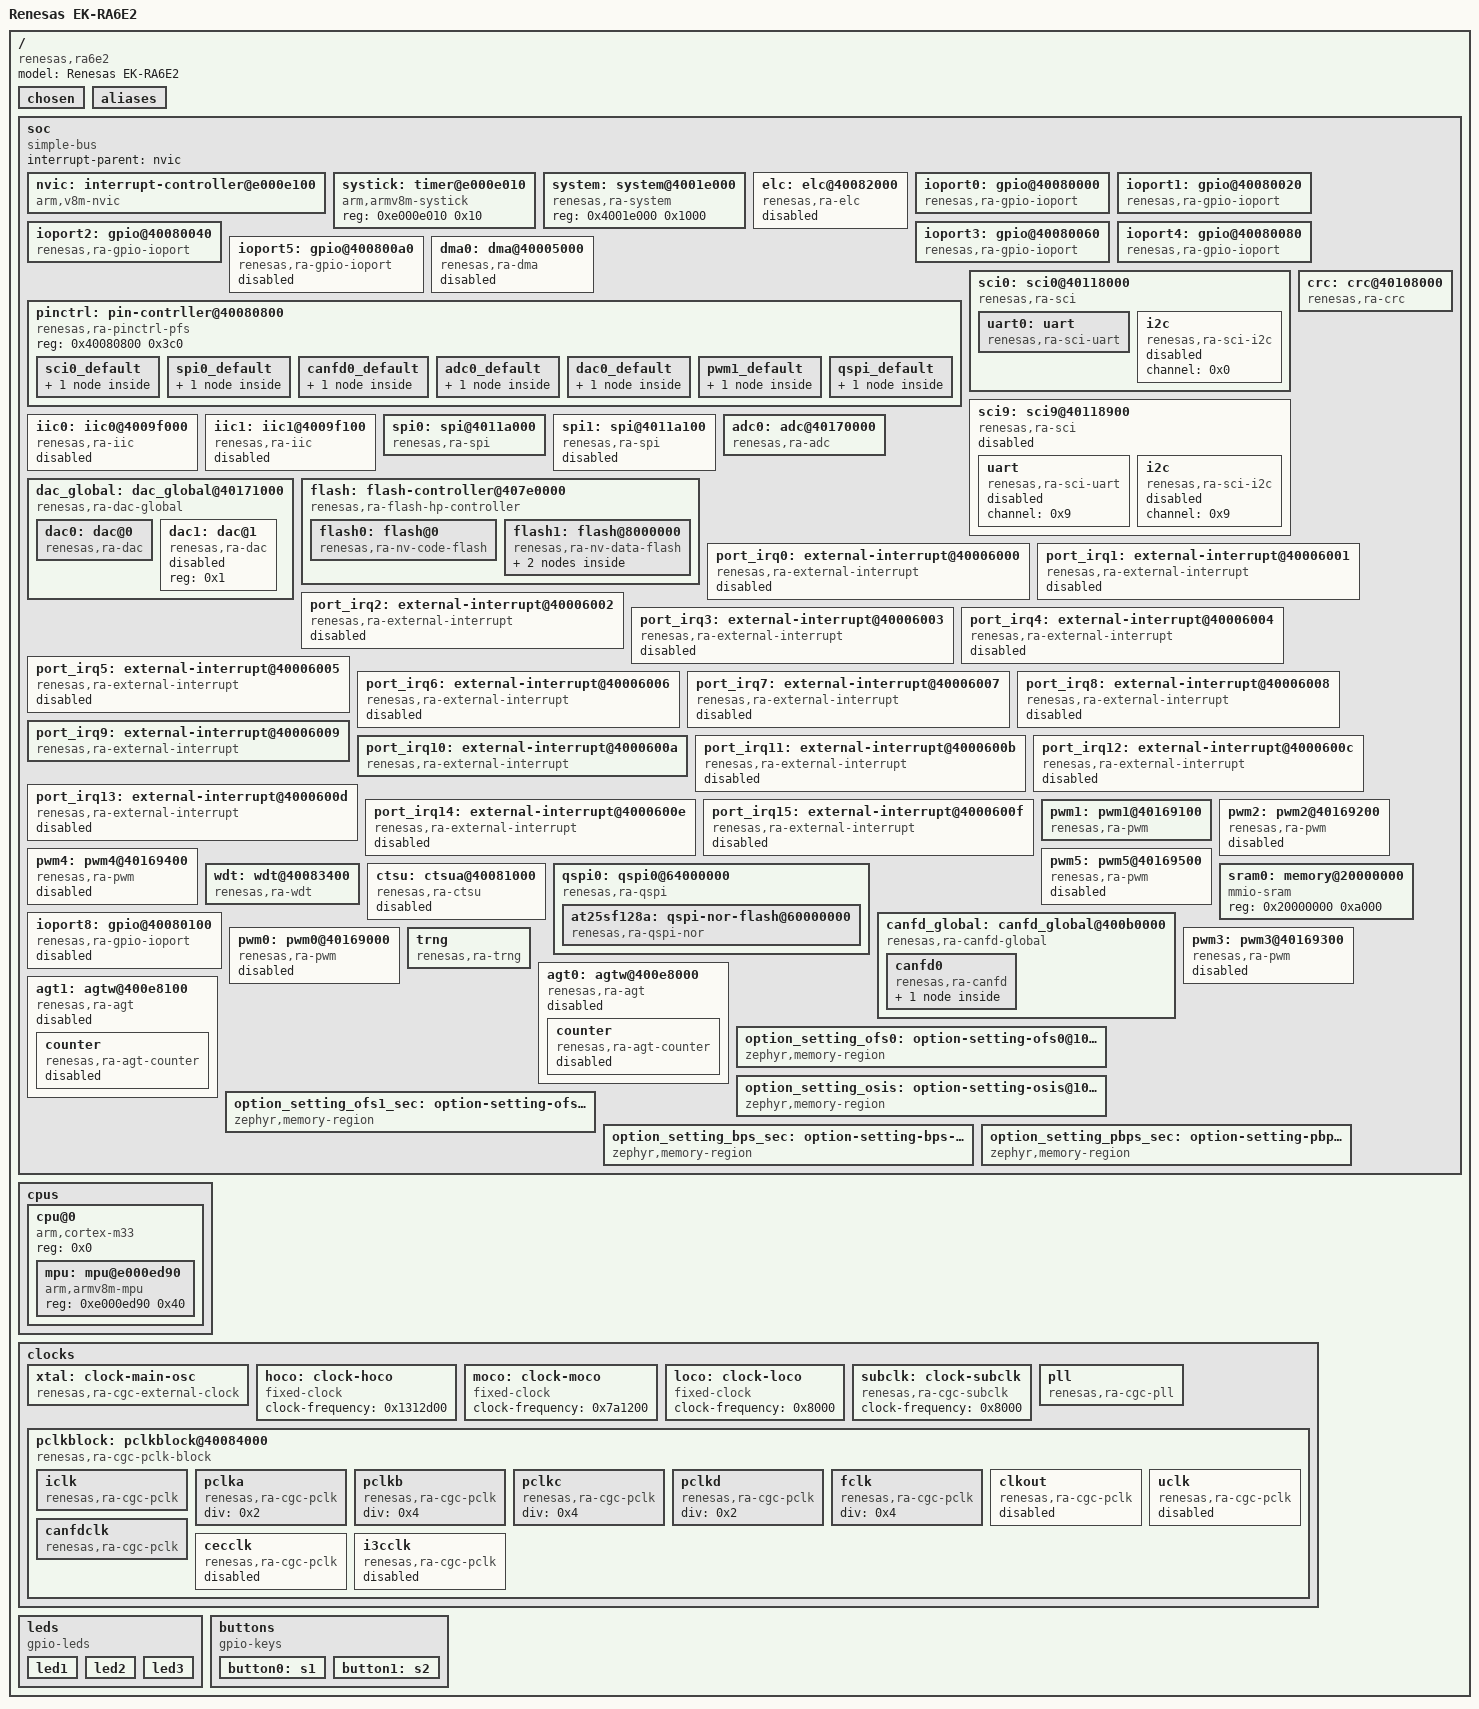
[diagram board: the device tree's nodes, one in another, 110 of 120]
/dts-v1/;

/* node '/' defined in zephyr/dts/common/skeleton.dtsi:9 */
/ {
	#address-cells = < 0x1 >;     /* in zephyr/dts/common/skeleton.dtsi:10 */
	#size-cells = < 0x1 >;        /* in zephyr/dts/common/skeleton.dtsi:11 */
	model = "Renesas EK-RA6E2";   /* in zephyr/boards/renesas/ek_ra6e2/ek_ra6e2.dts:16 */
	compatible = "renesas,ra6e2",
	             "renesas,ra";    /* in zephyr/boards/renesas/ek_ra6e2/ek_ra6e2.dts:17 */

	/* node '/chosen' defined in zephyr/dts/common/skeleton.dtsi:13 */
	chosen {
		zephyr,sram = &sram0;              /* in zephyr/boards/renesas/ek_ra6e2/ek_ra6e2.dts:20 */
		zephyr,flash-controller = &flash1; /* in zephyr/boards/renesas/ek_ra6e2/ek_ra6e2.dts:21 */
		zephyr,flash = &flash0;            /* in zephyr/boards/renesas/ek_ra6e2/ek_ra6e2.dts:22 */
		zephyr,console = &uart0;           /* in zephyr/boards/renesas/ek_ra6e2/ek_ra6e2.dts:23 */
		zephyr,shell-uart = &uart0;        /* in zephyr/boards/renesas/ek_ra6e2/ek_ra6e2.dts:24 */
		zephyr,canbus = &canfd0;           /* in zephyr/boards/renesas/ek_ra6e2/ek_ra6e2.dts:25 */
		zephyr,entropy = &trng;            /* in zephyr/boards/renesas/ek_ra6e2/ek_ra6e2.dts:26 */
		zephyr,crc = &crc;                 /* in zephyr/boards/renesas/ek_ra6e2/ek_ra6e2.dts:27 */
	};

	/* node '/aliases' defined in zephyr/dts/common/skeleton.dtsi:15 */
	aliases {
		led0 = &led1;     /* in zephyr/boards/renesas/ek_ra6e2/ek_ra6e2.dts:66 */
		sw0 = &button0;   /* in zephyr/boards/renesas/ek_ra6e2/ek_ra6e2.dts:67 */
		sw1 = &button1;   /* in zephyr/boards/renesas/ek_ra6e2/ek_ra6e2.dts:68 */
		watchdog0 = &wdt; /* in zephyr/boards/renesas/ek_ra6e2/ek_ra6e2.dts:69 */
	};

	/* node '/soc' defined in zephyr/dts/arm/armv8-m.dtsi:6 */
	soc {
		#address-cells = < 0x1 >;     /* in zephyr/dts/arm/armv8-m.dtsi:7 */
		#size-cells = < 0x1 >;        /* in zephyr/dts/arm/armv8-m.dtsi:8 */
		compatible = "simple-bus";    /* in zephyr/dts/arm/armv8-m.dtsi:9 */
		ranges;                       /* in zephyr/dts/arm/armv8-m.dtsi:11 */
		interrupt-parent = < &nvic >; /* in zephyr/dts/arm/renesas/ra/ra6/ra6-cm33-common.dtsi:34 */

		/* node '/soc/interrupt-controller@e000e100' defined in zephyr/dts/arm/armv8-m.dtsi:13 */
		nvic: interrupt-controller@e000e100 {
			#address-cells = < 0x1 >;            /* in zephyr/dts/arm/armv8-m.dtsi:14 */
			compatible = "arm,v8m-nvic";         /* in zephyr/dts/arm/armv8-m.dtsi:15 */
			reg = < 0xe000e100 0xc00 >;          /* in zephyr/dts/arm/armv8-m.dtsi:16 */
			interrupt-controller;                /* in zephyr/dts/arm/armv8-m.dtsi:17 */
			#interrupt-cells = < 0x2 >;          /* in zephyr/dts/arm/armv8-m.dtsi:18 */
			arm,num-irq-priority-bits = < 0x4 >; /* in zephyr/dts/arm/renesas/ra/ra6/ra6-cm33-common.dtsi:603 */
			phandle = < 0x1 >;                   /* in zephyr/dts/arm/renesas/ra/ra6/ra6-cm33-common.dtsi:34 */
		};

		/* node '/soc/timer@e000e010' defined in zephyr/dts/arm/armv8-m.dtsi:21 */
		systick: timer@e000e010 {
			compatible = "arm,armv8m-systick"; /* in zephyr/dts/arm/armv8-m.dtsi:22 */
			reg = < 0xe000e010 0x10 >;         /* in zephyr/dts/arm/armv8-m.dtsi:23 */
		};

		/* node '/soc/system@4001e000' defined in zephyr/dts/arm/renesas/ra/ra6/ra6-cm33-common.dtsi:36 */
		system: system@4001e000 {
			compatible = "renesas,ra-system"; /* in zephyr/dts/arm/renesas/ra/ra6/ra6-cm33-common.dtsi:37 */
			reg = < 0x4001e000 0x1000 >;      /* in zephyr/dts/arm/renesas/ra/ra6/ra6-cm33-common.dtsi:38 */
			status = "okay";                  /* in zephyr/dts/arm/renesas/ra/ra6/ra6-cm33-common.dtsi:39 */
		};

		/* node '/soc/elc@40082000' defined in zephyr/dts/arm/renesas/ra/ra6/ra6-cm33-common.dtsi:42 */
		elc: elc@40082000 {
			compatible = "renesas,ra-elc"; /* in zephyr/dts/arm/renesas/ra/ra6/ra6-cm33-common.dtsi:43 */
			reg = < 0x40082000 0x70 >;     /* in zephyr/dts/arm/renesas/ra/ra6/ra6-cm33-common.dtsi:44 */
			#renesas-elc-cells = < 0x2 >;  /* in zephyr/dts/arm/renesas/ra/ra6/ra6-cm33-common.dtsi:45 */
			clocks = < &pclkb 0x2 0xe >;   /* in zephyr/dts/arm/renesas/ra/ra6/ra6-cm33-common.dtsi:46 */
			status = "disabled";           /* in zephyr/dts/arm/renesas/ra/ra6/ra6-cm33-common.dtsi:47 */
		};

		/* node '/soc/gpio@40080000' defined in zephyr/dts/arm/renesas/ra/ra6/ra6-cm33-common.dtsi:50 */
		ioport0: gpio@40080000 {
			compatible = "renesas,ra-gpio-ioport";                                                                       /* in zephyr/dts/arm/renesas/ra/ra6/ra6-cm33-common.dtsi:51 */
			reg = < 0x40080000 0x20 >;                                                                                   /* in zephyr/dts/arm/renesas/ra/ra6/ra6-cm33-common.dtsi:52 */
			port = < 0x0 >;                                                                                              /* in zephyr/dts/arm/renesas/ra/ra6/ra6-cm33-common.dtsi:53 */
			gpio-controller;                                                                                             /* in zephyr/dts/arm/renesas/ra/ra6/ra6-cm33-common.dtsi:54 */
			#gpio-cells = < 0x2 >;                                                                                       /* in zephyr/dts/arm/renesas/ra/ra6/ra6-cm33-common.dtsi:55 */
			ngpios = < 0x10 >;                                                                                           /* in zephyr/dts/arm/renesas/ra/ra6/ra6-cm33-common.dtsi:56 */
			port-irqs = < &port_irq6 &port_irq7 &port_irq8 &port_irq9 &port_irq10 &port_irq11 &port_irq12 &port_irq13 >; /* in zephyr/dts/arm/renesas/ra/ra6/r7fa6e2bx.dtsi:291 */
			port-irq-names = "port-irq6",
			                 "port-irq7",
			                 "port-irq8",
			                 "port-irq9",
			                 "port-irq10",
			                 "port-irq11",
			                 "port-irq12",
			                 "port-irq13";                                                                               /* in zephyr/dts/arm/renesas/ra/ra6/r7fa6e2bx.dtsi:294 */
			port-irq6-pins = < 0x0 >;                                                                                    /* in zephyr/dts/arm/renesas/ra/ra6/r7fa6e2bx.dtsi:302 */
			port-irq7-pins = < 0x1 >;                                                                                    /* in zephyr/dts/arm/renesas/ra/ra6/r7fa6e2bx.dtsi:303 */
			port-irq8-pins = < 0x2 >;                                                                                    /* in zephyr/dts/arm/renesas/ra/ra6/r7fa6e2bx.dtsi:304 */
			port-irq9-pins = < 0x4 >;                                                                                    /* in zephyr/dts/arm/renesas/ra/ra6/r7fa6e2bx.dtsi:305 */
			port-irq10-pins = < 0x5 >;                                                                                   /* in zephyr/dts/arm/renesas/ra/ra6/r7fa6e2bx.dtsi:306 */
			port-irq11-pins = < 0x6 >;                                                                                   /* in zephyr/dts/arm/renesas/ra/ra6/r7fa6e2bx.dtsi:307 */
			port-irq12-pins = < 0x8 >;                                                                                   /* in zephyr/dts/arm/renesas/ra/ra6/r7fa6e2bx.dtsi:308 */
			port-irq13-pins = < 0xf >;                                                                                   /* in zephyr/dts/arm/renesas/ra/ra6/r7fa6e2bx.dtsi:309 */
			status = "okay";                                                                                             /* in zephyr/boards/renesas/ek_ra6e2/ek_ra6e2.dts:85 */
			phandle = < 0x23 >;                                                                                          /* in zephyr/boards/renesas/ek_ra6e2/ek_ra6e2.dts:53 */
		};

		/* node '/soc/gpio@40080020' defined in zephyr/dts/arm/renesas/ra/ra6/ra6-cm33-common.dtsi:60 */
		ioport1: gpio@40080020 {
			compatible = "renesas,ra-gpio-ioport";                                  /* in zephyr/dts/arm/renesas/ra/ra6/ra6-cm33-common.dtsi:61 */
			reg = < 0x40080020 0x20 >;                                              /* in zephyr/dts/arm/renesas/ra/ra6/ra6-cm33-common.dtsi:62 */
			port = < 0x1 >;                                                         /* in zephyr/dts/arm/renesas/ra/ra6/ra6-cm33-common.dtsi:63 */
			gpio-controller;                                                        /* in zephyr/dts/arm/renesas/ra/ra6/ra6-cm33-common.dtsi:64 */
			#gpio-cells = < 0x2 >;                                                  /* in zephyr/dts/arm/renesas/ra/ra6/ra6-cm33-common.dtsi:65 */
			ngpios = < 0x10 >;                                                      /* in zephyr/dts/arm/renesas/ra/ra6/ra6-cm33-common.dtsi:66 */
			port-irqs = < &port_irq0 &port_irq1 &port_irq2 &port_irq3 &port_irq4 >; /* in zephyr/dts/arm/renesas/ra/ra6/r7fa6e2bx.dtsi:313 */
			port-irq-names = "port-irq0",
			                 "port-irq1",
			                 "port-irq2",
			                 "port-irq3",
			                 "port-irq4";                                           /* in zephyr/dts/arm/renesas/ra/ra6/r7fa6e2bx.dtsi:315 */
			port-irq0-pins = < 0x5 >;                                               /* in zephyr/dts/arm/renesas/ra/ra6/r7fa6e2bx.dtsi:320 */
			port-irq1-pins = < 0x1 0x4 >;                                           /* in zephyr/dts/arm/renesas/ra/ra6/r7fa6e2bx.dtsi:321 */
			port-irq2-pins = < 0x0 >;                                               /* in zephyr/dts/arm/renesas/ra/ra6/r7fa6e2bx.dtsi:322 */
			port-irq3-pins = < 0xa >;                                               /* in zephyr/dts/arm/renesas/ra/ra6/r7fa6e2bx.dtsi:323 */
			port-irq4-pins = < 0xb >;                                               /* in zephyr/dts/arm/renesas/ra/ra6/r7fa6e2bx.dtsi:324 */
			status = "okay";                                                        /* in zephyr/boards/renesas/ek_ra6e2/ek_ra6e2.dts:89 */
			phandle = < 0x22 >;                                                     /* in zephyr/boards/renesas/ek_ra6e2/ek_ra6e2.dts:44 */
		};

		/* node '/soc/gpio@40080040' defined in zephyr/dts/arm/renesas/ra/ra6/ra6-cm33-common.dtsi:70 */
		ioport2: gpio@40080040 {
			compatible = "renesas,ra-gpio-ioport";                       /* in zephyr/dts/arm/renesas/ra/ra6/ra6-cm33-common.dtsi:71 */
			reg = < 0x40080040 0x20 >;                                   /* in zephyr/dts/arm/renesas/ra/ra6/ra6-cm33-common.dtsi:72 */
			port = < 0x2 >;                                              /* in zephyr/dts/arm/renesas/ra/ra6/ra6-cm33-common.dtsi:73 */
			gpio-controller;                                             /* in zephyr/dts/arm/renesas/ra/ra6/ra6-cm33-common.dtsi:74 */
			#gpio-cells = < 0x2 >;                                       /* in zephyr/dts/arm/renesas/ra/ra6/ra6-cm33-common.dtsi:75 */
			ngpios = < 0x10 >;                                           /* in zephyr/dts/arm/renesas/ra/ra6/ra6-cm33-common.dtsi:76 */
			port-irqs = < &port_irq0 &port_irq1 &port_irq2 &port_irq3 >; /* in zephyr/dts/arm/renesas/ra/ra6/r7fa6e2bx.dtsi:328 */
			port-irq-names = "port-irq0",
			                 "port-irq1",
			                 "port-irq2",
			                 "port-irq3";                                /* in zephyr/dts/arm/renesas/ra/ra6/r7fa6e2bx.dtsi:330 */
			port-irq0-pins = < 0x6 >;                                    /* in zephyr/dts/arm/renesas/ra/ra6/r7fa6e2bx.dtsi:334 */
			port-irq1-pins = < 0x5 >;                                    /* in zephyr/dts/arm/renesas/ra/ra6/r7fa6e2bx.dtsi:335 */
			port-irq2-pins = < 0xd >;                                    /* in zephyr/dts/arm/renesas/ra/ra6/r7fa6e2bx.dtsi:336 */
			port-irq3-pins = < 0xc >;                                    /* in zephyr/dts/arm/renesas/ra/ra6/r7fa6e2bx.dtsi:337 */
			status = "okay";                                             /* in zephyr/boards/renesas/ek_ra6e2/ek_ra6e2.dts:99 */
			phandle = < 0x20 >;                                          /* in zephyr/boards/renesas/ek_ra6e2/ek_ra6e2.dts:34 */
		};

		/* node '/soc/gpio@40080060' defined in zephyr/dts/arm/renesas/ra/ra6/ra6-cm33-common.dtsi:80 */
		ioport3: gpio@40080060 {
			compatible = "renesas,ra-gpio-ioport";            /* in zephyr/dts/arm/renesas/ra/ra6/ra6-cm33-common.dtsi:81 */
			reg = < 0x40080060 0x20 >;                        /* in zephyr/dts/arm/renesas/ra/ra6/ra6-cm33-common.dtsi:82 */
			port = < 0x3 >;                                   /* in zephyr/dts/arm/renesas/ra/ra6/ra6-cm33-common.dtsi:83 */
			gpio-controller;                                  /* in zephyr/dts/arm/renesas/ra/ra6/ra6-cm33-common.dtsi:84 */
			#gpio-cells = < 0x2 >;                            /* in zephyr/dts/arm/renesas/ra/ra6/ra6-cm33-common.dtsi:85 */
			ngpios = < 0x10 >;                                /* in zephyr/dts/arm/renesas/ra/ra6/ra6-cm33-common.dtsi:86 */
			port-irqs = < &port_irq5 &port_irq6 &port_irq9 >; /* in zephyr/dts/arm/renesas/ra/ra6/r7fa6e2bx.dtsi:341 */
			port-irq-names = "port-irq5",
			                 "port-irq6",
			                 "port-irq9";                     /* in zephyr/dts/arm/renesas/ra/ra6/r7fa6e2bx.dtsi:342 */
			port-irq5-pins = < 0x2 >;                         /* in zephyr/dts/arm/renesas/ra/ra6/r7fa6e2bx.dtsi:345 */
			port-irq6-pins = < 0x1 >;                         /* in zephyr/dts/arm/renesas/ra/ra6/r7fa6e2bx.dtsi:346 */
			port-irq9-pins = < 0x4 >;                         /* in zephyr/dts/arm/renesas/ra/ra6/r7fa6e2bx.dtsi:347 */
			status = "okay";                                  /* in zephyr/boards/renesas/ek_ra6e2/ek_ra6e2.dts:103 */
			phandle = < 0x24 >;                               /* in zephyr/boards/renesas/ek_ra6e2/ek_ra6e2.dts:59 */
		};

		/* node '/soc/gpio@40080080' defined in zephyr/dts/arm/renesas/ra/ra6/ra6-cm33-common.dtsi:90 */
		ioport4: gpio@40080080 {
			compatible = "renesas,ra-gpio-ioport";                                              /* in zephyr/dts/arm/renesas/ra/ra6/ra6-cm33-common.dtsi:91 */
			reg = < 0x40080080 0x20 >;                                                          /* in zephyr/dts/arm/renesas/ra/ra6/ra6-cm33-common.dtsi:92 */
			port = < 0x4 >;                                                                     /* in zephyr/dts/arm/renesas/ra/ra6/ra6-cm33-common.dtsi:93 */
			gpio-controller;                                                                    /* in zephyr/dts/arm/renesas/ra/ra6/ra6-cm33-common.dtsi:94 */
			#gpio-cells = < 0x2 >;                                                              /* in zephyr/dts/arm/renesas/ra/ra6/ra6-cm33-common.dtsi:95 */
			ngpios = < 0x10 >;                                                                  /* in zephyr/dts/arm/renesas/ra/ra6/ra6-cm33-common.dtsi:96 */
			port-irqs = < &port_irq0 &port_irq4 &port_irq5 &port_irq6 &port_irq7 &port_irq14 >; /* in zephyr/dts/arm/renesas/ra/ra6/r7fa6e2bx.dtsi:351 */
			port-irq-names = "port-irq0",
			                 "port-irq4",
			                 "port-irq5",
			                 "port-irq6",
			                 "port-irq7",
			                 "port-irq14";                                                      /* in zephyr/dts/arm/renesas/ra/ra6/r7fa6e2bx.dtsi:353 */
			port-irq0-pins = < 0x0 >;                                                           /* in zephyr/dts/arm/renesas/ra/ra6/r7fa6e2bx.dtsi:359 */
			port-irq4-pins = < 0x2 0xb >;                                                       /* in zephyr/dts/arm/renesas/ra/ra6/r7fa6e2bx.dtsi:360 */
			port-irq5-pins = < 0x1 0xa >;                                                       /* in zephyr/dts/arm/renesas/ra/ra6/r7fa6e2bx.dtsi:361 */
			port-irq6-pins = < 0x9 >;                                                           /* in zephyr/dts/arm/renesas/ra/ra6/r7fa6e2bx.dtsi:362 */
			port-irq7-pins = < 0x8 >;                                                           /* in zephyr/dts/arm/renesas/ra/ra6/r7fa6e2bx.dtsi:363 */
			port-irq14-pins = < 0x3 >;                                                          /* in zephyr/dts/arm/renesas/ra/ra6/r7fa6e2bx.dtsi:364 */
			status = "okay";                                                                    /* in zephyr/boards/renesas/ek_ra6e2/ek_ra6e2.dts:107 */
			phandle = < 0x21 >;                                                                 /* in zephyr/boards/renesas/ek_ra6e2/ek_ra6e2.dts:39 */
		};

		/* node '/soc/gpio@400800a0' defined in zephyr/dts/arm/renesas/ra/ra6/ra6-cm33-common.dtsi:101 */
		ioport5: gpio@400800a0 {
			compatible = "renesas,ra-gpio-ioport"; /* in zephyr/dts/arm/renesas/ra/ra6/ra6-cm33-common.dtsi:102 */
			reg = < 0x400800a0 0x20 >;             /* in zephyr/dts/arm/renesas/ra/ra6/ra6-cm33-common.dtsi:103 */
			port = < 0x5 >;                        /* in zephyr/dts/arm/renesas/ra/ra6/ra6-cm33-common.dtsi:104 */
			gpio-controller;                       /* in zephyr/dts/arm/renesas/ra/ra6/ra6-cm33-common.dtsi:105 */
			#gpio-cells = < 0x2 >;                 /* in zephyr/dts/arm/renesas/ra/ra6/ra6-cm33-common.dtsi:106 */
			ngpios = < 0x10 >;                     /* in zephyr/dts/arm/renesas/ra/ra6/ra6-cm33-common.dtsi:107 */
			status = "disabled";                   /* in zephyr/dts/arm/renesas/ra/ra6/ra6-cm33-common.dtsi:108 */
		};

		/* node '/soc/dma@40005000' defined in zephyr/dts/arm/renesas/ra/ra6/ra6-cm33-common.dtsi:111 */
		dma0: dma@40005000 {
			compatible = "renesas,ra-dma"; /* in zephyr/dts/arm/renesas/ra/ra6/ra6-cm33-common.dtsi:112 */
			reg = < 0x40005000 0x200 >,
			      < 0x40005200 0xa0 >;     /* in zephyr/dts/arm/renesas/ra/ra6/ra6-cm33-common.dtsi:113 */
			reg-names = "channel",
			            "common";          /* in zephyr/dts/arm/renesas/ra/ra6/ra6-cm33-common.dtsi:114 */
			clocks = < &iclk 0x0 0x16 >;   /* in zephyr/dts/arm/renesas/ra/ra6/ra6-cm33-common.dtsi:115 */
			dma-channels = < 0x8 >;        /* in zephyr/dts/arm/renesas/ra/ra6/ra6-cm33-common.dtsi:116 */
			#dma-cells = < 0x2 >;          /* in zephyr/dts/arm/renesas/ra/ra6/ra6-cm33-common.dtsi:117 */
			status = "disabled";           /* in zephyr/dts/arm/renesas/ra/ra6/ra6-cm33-common.dtsi:118 */
		};

		/* node '/soc/pin-contrller@40080800' defined in zephyr/dts/arm/renesas/ra/ra6/ra6-cm33-common.dtsi:121 */
		pinctrl: pin-contrller@40080800 {
			compatible = "renesas,ra-pinctrl-pfs"; /* in zephyr/dts/arm/renesas/ra/ra6/ra6-cm33-common.dtsi:122 */
			reg = < 0x40080800 0x3c0 >;            /* in zephyr/dts/arm/renesas/ra/ra6/ra6-cm33-common.dtsi:123 */
			status = "okay";                       /* in zephyr/dts/arm/renesas/ra/ra6/ra6-cm33-common.dtsi:124 */

			/* node '/soc/pin-contrller@40080800/sci0_default' defined in zephyr/boards/renesas/ek_ra6e2/ek_ra6e2-pinctrl.dtsi:7 */
			sci0_default: sci0_default {
				phandle = < 0x14 >; /* in zephyr/boards/renesas/ek_ra6e2/ek_ra6e2.dts:74 */

				/* node '/soc/pin-contrller@40080800/sci0_default/group1' defined in zephyr/boards/renesas/ek_ra6e2/ek_ra6e2-pinctrl.dtsi:8 */
				group1 {
					psels = < 0x24b4 >,
					        < 0x24a4 >; /* in zephyr/boards/renesas/ek_ra6e2/ek_ra6e2-pinctrl.dtsi:10 */
				};
			};

			/* node '/soc/pin-contrller@40080800/spi0_default' defined in zephyr/boards/renesas/ek_ra6e2/ek_ra6e2-pinctrl.dtsi:15 */
			spi0_default: spi0_default {
				phandle = < 0x15 >; /* in zephyr/boards/renesas/ek_ra6e2/ek_ra6e2.dts:93 */

				/* node '/soc/pin-contrller@40080800/spi0_default/group1' defined in zephyr/boards/renesas/ek_ra6e2/ek_ra6e2-pinctrl.dtsi:16 */
				group1 {
					psels = < 0x26a1 >,
					        < 0x2691 >,
					        < 0x26b1 >,
					        < 0x2613 >; /* in zephyr/boards/renesas/ek_ra6e2/ek_ra6e2-pinctrl.dtsi:18 */
				};
			};

			/* node '/soc/pin-contrller@40080800/canfd0_default' defined in zephyr/boards/renesas/ek_ra6e2/ek_ra6e2-pinctrl.dtsi:25 */
			canfd0_default: canfd0_default {
				phandle = < 0x1d >; /* in zephyr/boards/renesas/ek_ra6e2/ek_ra6e2.dts:138 */

				/* node '/soc/pin-contrller@40080800/canfd0_default/group1' defined in zephyr/boards/renesas/ek_ra6e2/ek_ra6e2-pinctrl.dtsi:26 */
				group1 {
					psels = < 0x3024 >,
					        < 0x3014 >;      /* in zephyr/boards/renesas/ek_ra6e2/ek_ra6e2-pinctrl.dtsi:28 */
					drive-strength = "high"; /* in zephyr/boards/renesas/ek_ra6e2/ek_ra6e2-pinctrl.dtsi:30 */
				};
			};

			/* node '/soc/pin-contrller@40080800/adc0_default' defined in zephyr/boards/renesas/ek_ra6e2/ek_ra6e2-pinctrl.dtsi:34 */
			adc0_default: adc0_default {
				phandle = < 0x16 >; /* in zephyr/boards/renesas/ek_ra6e2/ek_ra6e2.dts:151 */

				/* node '/soc/pin-contrller@40080800/adc0_default/group1' defined in zephyr/boards/renesas/ek_ra6e2/ek_ra6e2-pinctrl.dtsi:35 */
				group1 {
					psels = < 0x2000 >;    /* in zephyr/boards/renesas/ek_ra6e2/ek_ra6e2-pinctrl.dtsi:37 */
					renesas,analog-enable; /* in zephyr/boards/renesas/ek_ra6e2/ek_ra6e2-pinctrl.dtsi:38 */
				};
			};

			/* node '/soc/pin-contrller@40080800/dac0_default' defined in zephyr/boards/renesas/ek_ra6e2/ek_ra6e2-pinctrl.dtsi:42 */
			dac0_default: dac0_default {
				phandle = < 0x17 >; /* in zephyr/boards/renesas/ek_ra6e2/ek_ra6e2.dts:156 */

				/* node '/soc/pin-contrller@40080800/dac0_default/group1' defined in zephyr/boards/renesas/ek_ra6e2/ek_ra6e2-pinctrl.dtsi:43 */
				group1 {
					psels = < 0x20e0 >;    /* in zephyr/boards/renesas/ek_ra6e2/ek_ra6e2-pinctrl.dtsi:45 */
					renesas,analog-enable; /* in zephyr/boards/renesas/ek_ra6e2/ek_ra6e2-pinctrl.dtsi:46 */
				};
			};

			/* node '/soc/pin-contrller@40080800/pwm1_default' defined in zephyr/boards/renesas/ek_ra6e2/ek_ra6e2-pinctrl.dtsi:50 */
			pwm1_default: pwm1_default {
				phandle = < 0x1a >; /* in zephyr/boards/renesas/ek_ra6e2/ek_ra6e2.dts:172 */

				/* node '/soc/pin-contrller@40080800/pwm1_default/group1' defined in zephyr/boards/renesas/ek_ra6e2/ek_ra6e2-pinctrl.dtsi:51 */
				group1 {
					psels = < 0x2394 >,
					        < 0x2384 >; /* in zephyr/boards/renesas/ek_ra6e2/ek_ra6e2-pinctrl.dtsi:53 */
				};
			};

			/* node '/soc/pin-contrller@40080800/qspi_default' defined in zephyr/boards/renesas/ek_ra6e2/ek_ra6e2-pinctrl.dtsi:58 */
			qspi_default: qspi_default {
				phandle = < 0x1b >; /* in zephyr/boards/renesas/ek_ra6e2/ek_ra6e2.dts:202 */

				/* node '/soc/pin-contrller@40080800/qspi_default/group1' defined in zephyr/boards/renesas/ek_ra6e2/ek_ra6e2-pinctrl.dtsi:59 */
				group1 {
					psels = < 0x3101 >,
					        < 0x31c1 >,
					        < 0x3121 >,
					        < 0x3111 >,
					        < 0x3141 >,
					        < 0x3131 >; /* in zephyr/boards/renesas/ek_ra6e2/ek_ra6e2-pinctrl.dtsi:61 */
				};
			};
		};

		/* node '/soc/sci0@40118000' defined in zephyr/dts/arm/renesas/ra/ra6/ra6-cm33-common.dtsi:127 */
		sci0: sci0@40118000 {
			compatible = "renesas,ra-sci"; /* in zephyr/dts/arm/renesas/ra/ra6/ra6-cm33-common.dtsi:128 */
			interrupts = < 0x0 0x1 >,
			             < 0x1 0x1 >,
			             < 0x2 0x1 >,
			             < 0x3 0x1 >;      /* in zephyr/dts/arm/renesas/ra/ra6/ra6-cm33-common.dtsi:129 */
			interrupt-names = "rxi",
			                  "txi",
			                  "tei",
			                  "eri";       /* in zephyr/dts/arm/renesas/ra/ra6/ra6-cm33-common.dtsi:130 */
			reg = < 0x40118000 0x100 >;    /* in zephyr/dts/arm/renesas/ra/ra6/ra6-cm33-common.dtsi:131 */
			clocks = < &pclka 0x1 0x1f >;  /* in zephyr/dts/arm/renesas/ra/ra6/ra6-cm33-common.dtsi:132 */
			pinctrl-0 = < &sci0_default >; /* in zephyr/boards/renesas/ek_ra6e2/ek_ra6e2.dts:74 */
			pinctrl-names = "default";     /* in zephyr/boards/renesas/ek_ra6e2/ek_ra6e2.dts:75 */
			status = "okay";               /* in zephyr/boards/renesas/ek_ra6e2/ek_ra6e2.dts:76 */

			/* node '/soc/sci0@40118000/uart' defined in zephyr/dts/arm/renesas/ra/ra6/ra6-cm33-common.dtsi:135 */
			uart0: uart {
				compatible = "renesas,ra-sci-uart"; /* in zephyr/dts/arm/renesas/ra/ra6/ra6-cm33-common.dtsi:136 */
				channel = < 0x0 >;                  /* in zephyr/dts/arm/renesas/ra/ra6/ra6-cm33-common.dtsi:137 */
				current-speed = < 0x1c200 >;        /* in zephyr/boards/renesas/ek_ra6e2/ek_ra6e2.dts:79 */
				status = "okay";                    /* in zephyr/boards/renesas/ek_ra6e2/ek_ra6e2.dts:80 */
			};

			/* node '/soc/sci0@40118000/i2c' defined in zephyr/dts/arm/renesas/ra/ra6/ra6-cm33-common.dtsi:141 */
			i2c {
				compatible = "renesas,ra-sci-i2c"; /* in zephyr/dts/arm/renesas/ra/ra6/ra6-cm33-common.dtsi:142 */
				#address-cells = < 0x1 >;          /* in zephyr/dts/arm/renesas/ra/ra6/ra6-cm33-common.dtsi:143 */
				#size-cells = < 0x0 >;             /* in zephyr/dts/arm/renesas/ra/ra6/ra6-cm33-common.dtsi:144 */
				channel = < 0x0 >;                 /* in zephyr/dts/arm/renesas/ra/ra6/ra6-cm33-common.dtsi:145 */
				status = "disabled";               /* in zephyr/dts/arm/renesas/ra/ra6/ra6-cm33-common.dtsi:146 */
			};
		};

		/* node '/soc/sci9@40118900' defined in zephyr/dts/arm/renesas/ra/ra6/ra6-cm33-common.dtsi:150 */
		sci9: sci9@40118900 {
			compatible = "renesas,ra-sci"; /* in zephyr/dts/arm/renesas/ra/ra6/ra6-cm33-common.dtsi:151 */
			interrupts = < 0x4a 0x1 >,
			             < 0x4b 0x1 >,
			             < 0x4c 0x1 >,
			             < 0x4d 0x1 >;     /* in zephyr/dts/arm/renesas/ra/ra6/ra6-cm33-common.dtsi:152 */
			interrupt-names = "rxi",
			                  "txi",
			                  "tei",
			                  "eri";       /* in zephyr/dts/arm/renesas/ra/ra6/ra6-cm33-common.dtsi:153 */
			reg = < 0x40118900 0x100 >;    /* in zephyr/dts/arm/renesas/ra/ra6/ra6-cm33-common.dtsi:154 */
			clocks = < &pclka 0x1 0x16 >;  /* in zephyr/dts/arm/renesas/ra/ra6/ra6-cm33-common.dtsi:155 */
			status = "disabled";           /* in zephyr/dts/arm/renesas/ra/ra6/ra6-cm33-common.dtsi:156 */

			/* node '/soc/sci9@40118900/uart' defined in zephyr/dts/arm/renesas/ra/ra6/ra6-cm33-common.dtsi:158 */
			uart {
				compatible = "renesas,ra-sci-uart"; /* in zephyr/dts/arm/renesas/ra/ra6/ra6-cm33-common.dtsi:159 */
				channel = < 0x9 >;                  /* in zephyr/dts/arm/renesas/ra/ra6/ra6-cm33-common.dtsi:160 */
				status = "disabled";                /* in zephyr/dts/arm/renesas/ra/ra6/ra6-cm33-common.dtsi:161 */
			};

			/* node '/soc/sci9@40118900/i2c' defined in zephyr/dts/arm/renesas/ra/ra6/ra6-cm33-common.dtsi:164 */
			i2c {
				compatible = "renesas,ra-sci-i2c"; /* in zephyr/dts/arm/renesas/ra/ra6/ra6-cm33-common.dtsi:165 */
				#address-cells = < 0x1 >;          /* in zephyr/dts/arm/renesas/ra/ra6/ra6-cm33-common.dtsi:166 */
				#size-cells = < 0x0 >;             /* in zephyr/dts/arm/renesas/ra/ra6/ra6-cm33-common.dtsi:167 */
				channel = < 0x9 >;                 /* in zephyr/dts/arm/renesas/ra/ra6/ra6-cm33-common.dtsi:168 */
				status = "disabled";               /* in zephyr/dts/arm/renesas/ra/ra6/ra6-cm33-common.dtsi:169 */
			};
		};

		/* node '/soc/iic0@4009f000' defined in zephyr/dts/arm/renesas/ra/ra6/ra6-cm33-common.dtsi:173 */
		iic0: iic0@4009f000 {
			compatible = "renesas,ra-iic"; /* in zephyr/dts/arm/renesas/ra/ra6/ra6-cm33-common.dtsi:174 */
			channel = < 0x0 >;             /* in zephyr/dts/arm/renesas/ra/ra6/ra6-cm33-common.dtsi:175 */
			reg = < 0x4009f000 0x100 >;    /* in zephyr/dts/arm/renesas/ra/ra6/ra6-cm33-common.dtsi:176 */
			status = "disabled";           /* in zephyr/dts/arm/renesas/ra/ra6/ra6-cm33-common.dtsi:177 */
		};

		/* node '/soc/iic1@4009f100' defined in zephyr/dts/arm/renesas/ra/ra6/ra6-cm33-common.dtsi:180 */
		iic1: iic1@4009f100 {
			compatible = "renesas,ra-iic"; /* in zephyr/dts/arm/renesas/ra/ra6/ra6-cm33-common.dtsi:181 */
			channel = < 0x1 >;             /* in zephyr/dts/arm/renesas/ra/ra6/ra6-cm33-common.dtsi:182 */
			reg = < 0x4009f100 0x100 >;    /* in zephyr/dts/arm/renesas/ra/ra6/ra6-cm33-common.dtsi:183 */
			status = "disabled";           /* in zephyr/dts/arm/renesas/ra/ra6/ra6-cm33-common.dtsi:184 */
		};

		/* node '/soc/spi@4011a000' defined in zephyr/dts/arm/renesas/ra/ra6/ra6-cm33-common.dtsi:187 */
		spi0: spi@4011a000 {
			compatible = "renesas,ra-spi"; /* in zephyr/dts/arm/renesas/ra/ra6/ra6-cm33-common.dtsi:188 */
			#address-cells = < 0x1 >;      /* in zephyr/dts/arm/renesas/ra/ra6/ra6-cm33-common.dtsi:189 */
			#size-cells = < 0x0 >;         /* in zephyr/dts/arm/renesas/ra/ra6/ra6-cm33-common.dtsi:190 */
			channel = < 0x0 >;             /* in zephyr/dts/arm/renesas/ra/ra6/ra6-cm33-common.dtsi:191 */
			interrupts = < 0x4e 0x1 >,
			             < 0x4f 0x1 >,
			             < 0x50 0x1 >,
			             < 0x51 0x1 >;     /* in zephyr/dts/arm/renesas/ra/ra6/ra6-cm33-common.dtsi:192 */
			interrupt-names = "rxi",
			                  "txi",
			                  "tei",
			                  "eri";       /* in zephyr/dts/arm/renesas/ra/ra6/ra6-cm33-common.dtsi:193 */
			reg = < 0x4011a000 0x100 >;    /* in zephyr/dts/arm/renesas/ra/ra6/ra6-cm33-common.dtsi:194 */
			pinctrl-0 = < &spi0_default >; /* in zephyr/boards/renesas/ek_ra6e2/ek_ra6e2.dts:93 */
			pinctrl-names = "default";     /* in zephyr/boards/renesas/ek_ra6e2/ek_ra6e2.dts:94 */
			status = "okay";               /* in zephyr/boards/renesas/ek_ra6e2/ek_ra6e2.dts:95 */
		};

		/* node '/soc/spi@4011a100' defined in zephyr/dts/arm/renesas/ra/ra6/ra6-cm33-common.dtsi:198 */
		spi1: spi@4011a100 {
			compatible = "renesas,ra-spi"; /* in zephyr/dts/arm/renesas/ra/ra6/ra6-cm33-common.dtsi:199 */
			#address-cells = < 0x1 >;      /* in zephyr/dts/arm/renesas/ra/ra6/ra6-cm33-common.dtsi:200 */
			#size-cells = < 0x0 >;         /* in zephyr/dts/arm/renesas/ra/ra6/ra6-cm33-common.dtsi:201 */
			channel = < 0x1 >;             /* in zephyr/dts/arm/renesas/ra/ra6/ra6-cm33-common.dtsi:202 */
			interrupts = < 0x52 0x1 >,
			             < 0x53 0x1 >,
			             < 0x54 0x1 >,
			             < 0x55 0x1 >;     /* in zephyr/dts/arm/renesas/ra/ra6/ra6-cm33-common.dtsi:203 */
			interrupt-names = "rxi",
			                  "txi",
			                  "tei",
			                  "eri";       /* in zephyr/dts/arm/renesas/ra/ra6/ra6-cm33-common.dtsi:204 */
			reg = < 0x4011a100 0x100 >;    /* in zephyr/dts/arm/renesas/ra/ra6/ra6-cm33-common.dtsi:205 */
			status = "disabled";           /* in zephyr/dts/arm/renesas/ra/ra6/ra6-cm33-common.dtsi:206 */
		};

		/* node '/soc/adc@40170000' defined in zephyr/dts/arm/renesas/ra/ra6/ra6-cm33-common.dtsi:299 */
		adc0: adc@40170000 {
			compatible = "renesas,ra-adc";        /* in zephyr/dts/arm/renesas/ra/ra6/ra6-cm33-common.dtsi:300 */
			interrupts = < 0x26 0x1 >;            /* in zephyr/dts/arm/renesas/ra/ra6/ra6-cm33-common.dtsi:301 */
			interrupt-names = "scanend";          /* in zephyr/dts/arm/renesas/ra/ra6/ra6-cm33-common.dtsi:302 */
			reg = < 0x40170000 0x100 >;           /* in zephyr/dts/arm/renesas/ra/ra6/ra6-cm33-common.dtsi:303 */
			#io-channel-cells = < 0x1 >;          /* in zephyr/dts/arm/renesas/ra/ra6/ra6-cm33-common.dtsi:304 */
			vref-mv = < 0xce4 >;                  /* in zephyr/dts/arm/renesas/ra/ra6/ra6-cm33-common.dtsi:305 */
			channel-available-mask = < 0x139f7 >; /* in zephyr/dts/arm/renesas/ra/ra6/r7fa6e2bx.dtsi:42 */
			status = "okay";                      /* in zephyr/boards/renesas/ek_ra6e2/ek_ra6e2.dts:150 */
			pinctrl-0 = < &adc0_default >;        /* in zephyr/boards/renesas/ek_ra6e2/ek_ra6e2.dts:151 */
			pinctrl-names = "default";            /* in zephyr/boards/renesas/ek_ra6e2/ek_ra6e2.dts:152 */
		};

		/* node '/soc/crc@40108000' defined in zephyr/dts/arm/renesas/ra/ra6/ra6-cm33-common.dtsi:319 */
		crc: crc@40108000 {
			compatible = "renesas,ra-crc"; /* in zephyr/dts/arm/renesas/ra/ra6/ra6-cm33-common.dtsi:320 */
			reg = < 0x40108000 0x1000 >;   /* in zephyr/dts/arm/renesas/ra/ra6/ra6-cm33-common.dtsi:321 */
			clocks = < &pclka 0x2 0x1 >;   /* in zephyr/dts/arm/renesas/ra/ra6/ra6-cm33-common.dtsi:322 */
			status = "okay";               /* in zephyr/boards/renesas/ek_ra6e2/ek_ra6e2.dts:216 */
		};

		/* node '/soc/dac_global@40171000' defined in zephyr/dts/arm/renesas/ra/ra6/ra6-cm33-common.dtsi:326 */
		dac_global: dac_global@40171000 {
			compatible = "renesas,ra-dac-global"; /* in zephyr/dts/arm/renesas/ra/ra6/ra6-cm33-common.dtsi:327 */
			reg = < 0x40171000 0x10c4 >;          /* in zephyr/dts/arm/renesas/ra/ra6/ra6-cm33-common.dtsi:328 */
			#address-cells = < 0x1 >;             /* in zephyr/dts/arm/renesas/ra/ra6/ra6-cm33-common.dtsi:329 */
			#size-cells = < 0x0 >;                /* in zephyr/dts/arm/renesas/ra/ra6/ra6-cm33-common.dtsi:330 */
			has-output-amplifier;                 /* in zephyr/dts/arm/renesas/ra/ra6/r7fa6e2bx.dtsi:375 */

			/* node '/soc/dac_global@40171000/dac@0' defined in zephyr/dts/arm/renesas/ra/ra6/ra6-cm33-common.dtsi:332 */
			dac0: dac@0 {
				compatible = "renesas,ra-dac"; /* in zephyr/dts/arm/renesas/ra/ra6/ra6-cm33-common.dtsi:333 */
				#io-channel-cells = < 0x1 >;   /* in zephyr/dts/arm/renesas/ra/ra6/ra6-cm33-common.dtsi:334 */
				reg = < 0x0 >;                 /* in zephyr/dts/arm/renesas/ra/ra6/ra6-cm33-common.dtsi:335 */
				pinctrl-0 = < &dac0_default >; /* in zephyr/boards/renesas/ek_ra6e2/ek_ra6e2.dts:156 */
				pinctrl-names = "default";     /* in zephyr/boards/renesas/ek_ra6e2/ek_ra6e2.dts:157 */
				status = "okay";               /* in zephyr/boards/renesas/ek_ra6e2/ek_ra6e2.dts:158 */
			};

			/* node '/soc/dac_global@40171000/dac@1' defined in zephyr/dts/arm/renesas/ra/ra6/ra6-cm33-common.dtsi:339 */
			dac1: dac@1 {
				compatible = "renesas,ra-dac"; /* in zephyr/dts/arm/renesas/ra/ra6/ra6-cm33-common.dtsi:340 */
				#io-channel-cells = < 0x1 >;   /* in zephyr/dts/arm/renesas/ra/ra6/ra6-cm33-common.dtsi:341 */
				reg = < 0x1 >;                 /* in zephyr/dts/arm/renesas/ra/ra6/ra6-cm33-common.dtsi:342 */
				status = "disabled";           /* in zephyr/dts/arm/renesas/ra/ra6/ra6-cm33-common.dtsi:343 */
			};
		};

		/* node '/soc/flash-controller@407e0000' defined in zephyr/dts/arm/renesas/ra/ra6/ra6-cm33-common.dtsi:363 */
		flash: flash-controller@407e0000 {
			compatible = "renesas,ra-flash-hp-controller"; /* in zephyr/dts/arm/renesas/ra/ra6/ra6-cm33-common.dtsi:364 */
			reg = < 0x407e0000 0x10000 >;                  /* in zephyr/dts/arm/renesas/ra/ra6/ra6-cm33-common.dtsi:365 */
			#address-cells = < 0x1 >;                      /* in zephyr/dts/arm/renesas/ra/ra6/ra6-cm33-common.dtsi:366 */
			#size-cells = < 0x1 >;                         /* in zephyr/dts/arm/renesas/ra/ra6/ra6-cm33-common.dtsi:367 */
			interrupts = < 0x31 0x1 >,
			             < 0x32 0x1 >;                     /* in zephyr/dts/arm/renesas/ra/ra6/ra6-cm33-common.dtsi:368 */
			interrupt-names = "frdyi",
			                  "fiferr";                    /* in zephyr/dts/arm/renesas/ra/ra6/ra6-cm33-common.dtsi:369 */
			flash-hardware-version = < 0x28 >;             /* in zephyr/dts/arm/renesas/ra/ra6/r7fa6e2bb3cfm.dtsi:12 */
			#erase-block-cells = < 0x2 >;                  /* in zephyr/dts/arm/renesas/ra/ra6/r7fa6e2bb3cfm.dtsi:13 */
			phandle = < 0x18 >;                            /* in zephyr/dts/arm/renesas/ra/ra6/r7fa6e2bb3cfm.dtsi:20 */

			/* node '/soc/flash-controller@407e0000/flash@0' defined in zephyr/dts/arm/renesas/ra/ra6/r7fa6e2bb3cfm.dtsi:15 */
			flash0: flash@0 {
				compatible = "renesas,ra-nv-code-flash"; /* in zephyr/dts/arm/renesas/ra/ra6/r7fa6e2bb3cfm.dtsi:16 */
				reg = < 0x0 0x40000 >;                   /* in zephyr/dts/arm/renesas/ra/ra6/r7fa6e2bb3cfm.dtsi:17 */
				write-block-size = < 0x80 >;             /* in zephyr/dts/arm/renesas/ra/ra6/r7fa6e2bb3cfm.dtsi:18 */
				erase-block-size = < 0x8000 >;           /* in zephyr/dts/arm/renesas/ra/ra6/r7fa6e2bb3cfm.dtsi:19 */
				erase-blocks = < &flash 0x8 0x2000 >,
				               < &flash 0x6 0x8000 >;    /* in zephyr/dts/arm/renesas/ra/ra6/r7fa6e2bb3cfm.dtsi:20 */
				programming-enable;                      /* in zephyr/dts/arm/renesas/ra/ra6/r7fa6e2bb3cfm.dtsi:21 */
			};

			/* node '/soc/flash-controller@407e0000/flash@8000000' defined in zephyr/dts/arm/renesas/ra/ra6/r7fa6e2bb3cfm.dtsi:24 */
			flash1: flash@8000000 {
				compatible = "renesas,ra-nv-data-flash"; /* in zephyr/dts/arm/renesas/ra/ra6/r7fa6e2bb3cfm.dtsi:25 */
				reg = < 0x8000000 0x1000 >;              /* in zephyr/dts/arm/renesas/ra/ra6/r7fa6e2bb3cfm.dtsi:26 */
				write-block-size = < 0x4 >;              /* in zephyr/dts/arm/renesas/ra/ra6/r7fa6e2bb3cfm.dtsi:27 */
				erase-block-size = < 0x40 >;             /* in zephyr/dts/arm/renesas/ra/ra6/r7fa6e2bb3cfm.dtsi:28 */
				programming-enable;                      /* in zephyr/dts/arm/renesas/ra/ra6/r7fa6e2bb3cfm.dtsi:29 */
				erase-value-undefined;                   /* in zephyr/dts/arm/renesas/ra/ra6/r7fa6e2bb3cfm.dtsi:30 */

				/* node '/soc/flash-controller@407e0000/flash@8000000/partitions' defined in zephyr/boards/renesas/ek_ra6e2/ek_ra6e2.dts:185 */
				partitions {
					compatible = "fixed-partitions"; /* in zephyr/boards/renesas/ek_ra6e2/ek_ra6e2.dts:186 */
					#address-cells = < 0x1 >;        /* in zephyr/boards/renesas/ek_ra6e2/ek_ra6e2.dts:187 */
					#size-cells = < 0x1 >;           /* in zephyr/boards/renesas/ek_ra6e2/ek_ra6e2.dts:188 */

					/* node '/soc/flash-controller@407e0000/flash@8000000/partitions/partition@0' defined in zephyr/boards/renesas/ek_ra6e2/ek_ra6e2.dts:190 */
					storage_partition: partition@0 {
						label = "storage";    /* in zephyr/boards/renesas/ek_ra6e2/ek_ra6e2.dts:191 */
						reg = < 0x0 0x1000 >; /* in zephyr/boards/renesas/ek_ra6e2/ek_ra6e2.dts:192 */
					};
				};
			};
		};

		/* node '/soc/external-interrupt@40006000' defined in zephyr/dts/arm/renesas/ra/ra6/ra6-cm33-common.dtsi:372 */
		port_irq0: external-interrupt@40006000 {
			compatible = "renesas,ra-external-interrupt"; /* in zephyr/dts/arm/renesas/ra/ra6/ra6-cm33-common.dtsi:373 */
			reg = < 0x40006000 0x1 >;                     /* in zephyr/dts/arm/renesas/ra/ra6/ra6-cm33-common.dtsi:374 */
			channel = < 0x0 >;                            /* in zephyr/dts/arm/renesas/ra/ra6/ra6-cm33-common.dtsi:375 */
			renesas,sample-clock-div = < 0x40 >;          /* in zephyr/dts/arm/renesas/ra/ra6/ra6-cm33-common.dtsi:376 */
			#port-irq-cells = < 0x0 >;                    /* in zephyr/dts/arm/renesas/ra/ra6/ra6-cm33-common.dtsi:377 */
			status = "disabled";                          /* in zephyr/dts/arm/renesas/ra/ra6/ra6-cm33-common.dtsi:378 */
			phandle = < 0xb >;                            /* in zephyr/dts/arm/renesas/ra/ra6/r7fa6e2bx.dtsi:313 */
		};

		/* node '/soc/external-interrupt@40006001' defined in zephyr/dts/arm/renesas/ra/ra6/ra6-cm33-common.dtsi:381 */
		port_irq1: external-interrupt@40006001 {
			compatible = "renesas,ra-external-interrupt"; /* in zephyr/dts/arm/renesas/ra/ra6/ra6-cm33-common.dtsi:382 */
			reg = < 0x40006001 0x1 >;                     /* in zephyr/dts/arm/renesas/ra/ra6/ra6-cm33-common.dtsi:383 */
			channel = < 0x1 >;                            /* in zephyr/dts/arm/renesas/ra/ra6/ra6-cm33-common.dtsi:384 */
			renesas,sample-clock-div = < 0x40 >;          /* in zephyr/dts/arm/renesas/ra/ra6/ra6-cm33-common.dtsi:385 */
			#port-irq-cells = < 0x0 >;                    /* in zephyr/dts/arm/renesas/ra/ra6/ra6-cm33-common.dtsi:386 */
			status = "disabled";                          /* in zephyr/dts/arm/renesas/ra/ra6/ra6-cm33-common.dtsi:387 */
			phandle = < 0xc >;                            /* in zephyr/dts/arm/renesas/ra/ra6/r7fa6e2bx.dtsi:313 */
		};

		/* node '/soc/external-interrupt@40006002' defined in zephyr/dts/arm/renesas/ra/ra6/ra6-cm33-common.dtsi:390 */
		port_irq2: external-interrupt@40006002 {
			compatible = "renesas,ra-external-interrupt"; /* in zephyr/dts/arm/renesas/ra/ra6/ra6-cm33-common.dtsi:391 */
			reg = < 0x40006002 0x1 >;                     /* in zephyr/dts/arm/renesas/ra/ra6/ra6-cm33-common.dtsi:392 */
			channel = < 0x2 >;                            /* in zephyr/dts/arm/renesas/ra/ra6/ra6-cm33-common.dtsi:393 */
			renesas,sample-clock-div = < 0x40 >;          /* in zephyr/dts/arm/renesas/ra/ra6/ra6-cm33-common.dtsi:394 */
			#port-irq-cells = < 0x0 >;                    /* in zephyr/dts/arm/renesas/ra/ra6/ra6-cm33-common.dtsi:395 */
			status = "disabled";                          /* in zephyr/dts/arm/renesas/ra/ra6/ra6-cm33-common.dtsi:396 */
			phandle = < 0xd >;                            /* in zephyr/dts/arm/renesas/ra/ra6/r7fa6e2bx.dtsi:313 */
		};

		/* node '/soc/external-interrupt@40006003' defined in zephyr/dts/arm/renesas/ra/ra6/ra6-cm33-common.dtsi:399 */
		port_irq3: external-interrupt@40006003 {
			compatible = "renesas,ra-external-interrupt"; /* in zephyr/dts/arm/renesas/ra/ra6/ra6-cm33-common.dtsi:400 */
			reg = < 0x40006003 0x1 >;                     /* in zephyr/dts/arm/renesas/ra/ra6/ra6-cm33-common.dtsi:401 */
			channel = < 0x3 >;                            /* in zephyr/dts/arm/renesas/ra/ra6/ra6-cm33-common.dtsi:402 */
			renesas,sample-clock-div = < 0x40 >;          /* in zephyr/dts/arm/renesas/ra/ra6/ra6-cm33-common.dtsi:403 */
			#port-irq-cells = < 0x0 >;                    /* in zephyr/dts/arm/renesas/ra/ra6/ra6-cm33-common.dtsi:404 */
			status = "disabled";                          /* in zephyr/dts/arm/renesas/ra/ra6/ra6-cm33-common.dtsi:405 */
			phandle = < 0xe >;                            /* in zephyr/dts/arm/renesas/ra/ra6/r7fa6e2bx.dtsi:313 */
		};

		/* node '/soc/external-interrupt@40006004' defined in zephyr/dts/arm/renesas/ra/ra6/ra6-cm33-common.dtsi:408 */
		port_irq4: external-interrupt@40006004 {
			compatible = "renesas,ra-external-interrupt"; /* in zephyr/dts/arm/renesas/ra/ra6/ra6-cm33-common.dtsi:409 */
			reg = < 0x40006004 0x1 >;                     /* in zephyr/dts/arm/renesas/ra/ra6/ra6-cm33-common.dtsi:410 */
			channel = < 0x4 >;                            /* in zephyr/dts/arm/renesas/ra/ra6/ra6-cm33-common.dtsi:411 */
			renesas,sample-clock-div = < 0x40 >;          /* in zephyr/dts/arm/renesas/ra/ra6/ra6-cm33-common.dtsi:412 */
			#port-irq-cells = < 0x0 >;                    /* in zephyr/dts/arm/renesas/ra/ra6/ra6-cm33-common.dtsi:413 */
			status = "disabled";                          /* in zephyr/dts/arm/renesas/ra/ra6/ra6-cm33-common.dtsi:414 */
			phandle = < 0xf >;                            /* in zephyr/dts/arm/renesas/ra/ra6/r7fa6e2bx.dtsi:313 */
		};

		/* node '/soc/external-interrupt@40006005' defined in zephyr/dts/arm/renesas/ra/ra6/ra6-cm33-common.dtsi:417 */
		port_irq5: external-interrupt@40006005 {
			compatible = "renesas,ra-external-interrupt"; /* in zephyr/dts/arm/renesas/ra/ra6/ra6-cm33-common.dtsi:418 */
			reg = < 0x40006005 0x1 >;                     /* in zephyr/dts/arm/renesas/ra/ra6/ra6-cm33-common.dtsi:419 */
			channel = < 0x5 >;                            /* in zephyr/dts/arm/renesas/ra/ra6/ra6-cm33-common.dtsi:420 */
			renesas,sample-clock-div = < 0x40 >;          /* in zephyr/dts/arm/renesas/ra/ra6/ra6-cm33-common.dtsi:421 */
			#port-irq-cells = < 0x0 >;                    /* in zephyr/dts/arm/renesas/ra/ra6/ra6-cm33-common.dtsi:422 */
			status = "disabled";                          /* in zephyr/dts/arm/renesas/ra/ra6/ra6-cm33-common.dtsi:423 */
			phandle = < 0x10 >;                           /* in zephyr/dts/arm/renesas/ra/ra6/r7fa6e2bx.dtsi:341 */
		};

		/* node '/soc/external-interrupt@40006006' defined in zephyr/dts/arm/renesas/ra/ra6/ra6-cm33-common.dtsi:426 */
		port_irq6: external-interrupt@40006006 {
			compatible = "renesas,ra-external-interrupt"; /* in zephyr/dts/arm/renesas/ra/ra6/ra6-cm33-common.dtsi:427 */
			reg = < 0x40006006 0x1 >;                     /* in zephyr/dts/arm/renesas/ra/ra6/ra6-cm33-common.dtsi:428 */
			channel = < 0x6 >;                            /* in zephyr/dts/arm/renesas/ra/ra6/ra6-cm33-common.dtsi:429 */
			renesas,sample-clock-div = < 0x40 >;          /* in zephyr/dts/arm/renesas/ra/ra6/ra6-cm33-common.dtsi:430 */
			#port-irq-cells = < 0x0 >;                    /* in zephyr/dts/arm/renesas/ra/ra6/ra6-cm33-common.dtsi:431 */
			status = "disabled";                          /* in zephyr/dts/arm/renesas/ra/ra6/ra6-cm33-common.dtsi:432 */
			phandle = < 0x3 >;                            /* in zephyr/dts/arm/renesas/ra/ra6/r7fa6e2bx.dtsi:291 */
		};

		/* node '/soc/external-interrupt@40006007' defined in zephyr/dts/arm/renesas/ra/ra6/ra6-cm33-common.dtsi:435 */
		port_irq7: external-interrupt@40006007 {
			compatible = "renesas,ra-external-interrupt"; /* in zephyr/dts/arm/renesas/ra/ra6/ra6-cm33-common.dtsi:436 */
			reg = < 0x40006007 0x1 >;                     /* in zephyr/dts/arm/renesas/ra/ra6/ra6-cm33-common.dtsi:437 */
			channel = < 0x7 >;                            /* in zephyr/dts/arm/renesas/ra/ra6/ra6-cm33-common.dtsi:438 */
			renesas,sample-clock-div = < 0x40 >;          /* in zephyr/dts/arm/renesas/ra/ra6/ra6-cm33-common.dtsi:439 */
			#port-irq-cells = < 0x0 >;                    /* in zephyr/dts/arm/renesas/ra/ra6/ra6-cm33-common.dtsi:440 */
			status = "disabled";                          /* in zephyr/dts/arm/renesas/ra/ra6/ra6-cm33-common.dtsi:441 */
			phandle = < 0x4 >;                            /* in zephyr/dts/arm/renesas/ra/ra6/r7fa6e2bx.dtsi:291 */
		};

		/* node '/soc/external-interrupt@40006008' defined in zephyr/dts/arm/renesas/ra/ra6/ra6-cm33-common.dtsi:444 */
		port_irq8: external-interrupt@40006008 {
			compatible = "renesas,ra-external-interrupt"; /* in zephyr/dts/arm/renesas/ra/ra6/ra6-cm33-common.dtsi:445 */
			reg = < 0x40006008 0x1 >;                     /* in zephyr/dts/arm/renesas/ra/ra6/ra6-cm33-common.dtsi:446 */
			channel = < 0x8 >;                            /* in zephyr/dts/arm/renesas/ra/ra6/ra6-cm33-common.dtsi:447 */
			renesas,sample-clock-div = < 0x40 >;          /* in zephyr/dts/arm/renesas/ra/ra6/ra6-cm33-common.dtsi:448 */
			#port-irq-cells = < 0x0 >;                    /* in zephyr/dts/arm/renesas/ra/ra6/ra6-cm33-common.dtsi:449 */
			status = "disabled";                          /* in zephyr/dts/arm/renesas/ra/ra6/ra6-cm33-common.dtsi:450 */
			phandle = < 0x5 >;                            /* in zephyr/dts/arm/renesas/ra/ra6/r7fa6e2bx.dtsi:291 */
		};

		/* node '/soc/external-interrupt@40006009' defined in zephyr/dts/arm/renesas/ra/ra6/ra6-cm33-common.dtsi:453 */
		port_irq9: external-interrupt@40006009 {
			compatible = "renesas,ra-external-interrupt"; /* in zephyr/dts/arm/renesas/ra/ra6/ra6-cm33-common.dtsi:454 */
			reg = < 0x40006009 0x1 >;                     /* in zephyr/dts/arm/renesas/ra/ra6/ra6-cm33-common.dtsi:455 */
			channel = < 0x9 >;                            /* in zephyr/dts/arm/renesas/ra/ra6/ra6-cm33-common.dtsi:456 */
			renesas,sample-clock-div = < 0x40 >;          /* in zephyr/dts/arm/renesas/ra/ra6/ra6-cm33-common.dtsi:457 */
			#port-irq-cells = < 0x0 >;                    /* in zephyr/dts/arm/renesas/ra/ra6/ra6-cm33-common.dtsi:458 */
			interrupts = < 0x4 0xc >;                     /* in zephyr/boards/renesas/ek_ra6e2/ek_ra6e2.dts:162 */
			status = "okay";                              /* in zephyr/boards/renesas/ek_ra6e2/ek_ra6e2.dts:163 */
			phandle = < 0x6 >;                            /* in zephyr/dts/arm/renesas/ra/ra6/r7fa6e2bx.dtsi:291 */
		};

		/* node '/soc/external-interrupt@4000600a' defined in zephyr/dts/arm/renesas/ra/ra6/ra6-cm33-common.dtsi:462 */
		port_irq10: external-interrupt@4000600a {
			compatible = "renesas,ra-external-interrupt"; /* in zephyr/dts/arm/renesas/ra/ra6/ra6-cm33-common.dtsi:463 */
			reg = < 0x4000600a 0x1 >;                     /* in zephyr/dts/arm/renesas/ra/ra6/ra6-cm33-common.dtsi:464 */
			channel = < 0xa >;                            /* in zephyr/dts/arm/renesas/ra/ra6/ra6-cm33-common.dtsi:465 */
			renesas,sample-clock-div = < 0x40 >;          /* in zephyr/dts/arm/renesas/ra/ra6/ra6-cm33-common.dtsi:466 */
			#port-irq-cells = < 0x0 >;                    /* in zephyr/dts/arm/renesas/ra/ra6/ra6-cm33-common.dtsi:467 */
			interrupts = < 0x5 0xc >;                     /* in zephyr/boards/renesas/ek_ra6e2/ek_ra6e2.dts:167 */
			status = "okay";                              /* in zephyr/boards/renesas/ek_ra6e2/ek_ra6e2.dts:168 */
			phandle = < 0x7 >;                            /* in zephyr/dts/arm/renesas/ra/ra6/r7fa6e2bx.dtsi:291 */
		};

		/* node '/soc/external-interrupt@4000600b' defined in zephyr/dts/arm/renesas/ra/ra6/ra6-cm33-common.dtsi:471 */
		port_irq11: external-interrupt@4000600b {
			compatible = "renesas,ra-external-interrupt"; /* in zephyr/dts/arm/renesas/ra/ra6/ra6-cm33-common.dtsi:472 */
			reg = < 0x4000600b 0x1 >;                     /* in zephyr/dts/arm/renesas/ra/ra6/ra6-cm33-common.dtsi:473 */
			channel = < 0xb >;                            /* in zephyr/dts/arm/renesas/ra/ra6/ra6-cm33-common.dtsi:474 */
			renesas,sample-clock-div = < 0x40 >;          /* in zephyr/dts/arm/renesas/ra/ra6/ra6-cm33-common.dtsi:475 */
			#port-irq-cells = < 0x0 >;                    /* in zephyr/dts/arm/renesas/ra/ra6/ra6-cm33-common.dtsi:476 */
			status = "disabled";                          /* in zephyr/dts/arm/renesas/ra/ra6/ra6-cm33-common.dtsi:477 */
			phandle = < 0x8 >;                            /* in zephyr/dts/arm/renesas/ra/ra6/r7fa6e2bx.dtsi:291 */
		};

		/* node '/soc/external-interrupt@4000600c' defined in zephyr/dts/arm/renesas/ra/ra6/ra6-cm33-common.dtsi:480 */
		port_irq12: external-interrupt@4000600c {
			compatible = "renesas,ra-external-interrupt"; /* in zephyr/dts/arm/renesas/ra/ra6/ra6-cm33-common.dtsi:481 */
			reg = < 0x4000600c 0x1 >;                     /* in zephyr/dts/arm/renesas/ra/ra6/ra6-cm33-common.dtsi:482 */
			channel = < 0xc >;                            /* in zephyr/dts/arm/renesas/ra/ra6/ra6-cm33-common.dtsi:483 */
			renesas,sample-clock-div = < 0x40 >;          /* in zephyr/dts/arm/renesas/ra/ra6/ra6-cm33-common.dtsi:484 */
			#port-irq-cells = < 0x0 >;                    /* in zephyr/dts/arm/renesas/ra/ra6/ra6-cm33-common.dtsi:485 */
			status = "disabled";                          /* in zephyr/dts/arm/renesas/ra/ra6/ra6-cm33-common.dtsi:486 */
			phandle = < 0x9 >;                            /* in zephyr/dts/arm/renesas/ra/ra6/r7fa6e2bx.dtsi:291 */
		};

		/* node '/soc/external-interrupt@4000600d' defined in zephyr/dts/arm/renesas/ra/ra6/ra6-cm33-common.dtsi:489 */
		port_irq13: external-interrupt@4000600d {
			compatible = "renesas,ra-external-interrupt"; /* in zephyr/dts/arm/renesas/ra/ra6/ra6-cm33-common.dtsi:490 */
			reg = < 0x4000600d 0x1 >;                     /* in zephyr/dts/arm/renesas/ra/ra6/ra6-cm33-common.dtsi:491 */
			channel = < 0xd >;                            /* in zephyr/dts/arm/renesas/ra/ra6/ra6-cm33-common.dtsi:492 */
			renesas,sample-clock-div = < 0x40 >;          /* in zephyr/dts/arm/renesas/ra/ra6/ra6-cm33-common.dtsi:493 */
			#port-irq-cells = < 0x0 >;                    /* in zephyr/dts/arm/renesas/ra/ra6/ra6-cm33-common.dtsi:494 */
			status = "disabled";                          /* in zephyr/dts/arm/renesas/ra/ra6/ra6-cm33-common.dtsi:495 */
			phandle = < 0xa >;                            /* in zephyr/dts/arm/renesas/ra/ra6/r7fa6e2bx.dtsi:291 */
		};

		/* node '/soc/external-interrupt@4000600e' defined in zephyr/dts/arm/renesas/ra/ra6/ra6-cm33-common.dtsi:498 */
		port_irq14: external-interrupt@4000600e {
			compatible = "renesas,ra-external-interrupt"; /* in zephyr/dts/arm/renesas/ra/ra6/ra6-cm33-common.dtsi:499 */
			reg = < 0x4000600e 0x1 >;                     /* in zephyr/dts/arm/renesas/ra/ra6/ra6-cm33-common.dtsi:500 */
			channel = < 0xe >;                            /* in zephyr/dts/arm/renesas/ra/ra6/ra6-cm33-common.dtsi:501 */
			renesas,sample-clock-div = < 0x40 >;          /* in zephyr/dts/arm/renesas/ra/ra6/ra6-cm33-common.dtsi:502 */
			#port-irq-cells = < 0x0 >;                    /* in zephyr/dts/arm/renesas/ra/ra6/ra6-cm33-common.dtsi:503 */
			status = "disabled";                          /* in zephyr/dts/arm/renesas/ra/ra6/ra6-cm33-common.dtsi:504 */
			phandle = < 0x11 >;                           /* in zephyr/dts/arm/renesas/ra/ra6/r7fa6e2bx.dtsi:351 */
		};

		/* node '/soc/external-interrupt@4000600f' defined in zephyr/dts/arm/renesas/ra/ra6/ra6-cm33-common.dtsi:507 */
		port_irq15: external-interrupt@4000600f {
			compatible = "renesas,ra-external-interrupt"; /* in zephyr/dts/arm/renesas/ra/ra6/ra6-cm33-common.dtsi:508 */
			reg = < 0x4000600f 0x1 >;                     /* in zephyr/dts/arm/renesas/ra/ra6/ra6-cm33-common.dtsi:509 */
			channel = < 0xf >;                            /* in zephyr/dts/arm/renesas/ra/ra6/ra6-cm33-common.dtsi:510 */
			renesas,sample-clock-div = < 0x40 >;          /* in zephyr/dts/arm/renesas/ra/ra6/ra6-cm33-common.dtsi:511 */
			#port-irq-cells = < 0x0 >;                    /* in zephyr/dts/arm/renesas/ra/ra6/ra6-cm33-common.dtsi:512 */
			status = "disabled";                          /* in zephyr/dts/arm/renesas/ra/ra6/ra6-cm33-common.dtsi:513 */
		};

		/* node '/soc/pwm1@40169100' defined in zephyr/dts/arm/renesas/ra/ra6/ra6-cm33-common.dtsi:516 */
		pwm1: pwm1@40169100 {
			compatible = "renesas,ra-pwm"; /* in zephyr/dts/arm/renesas/ra/ra6/ra6-cm33-common.dtsi:517 */
			channel = < 0x1 >;             /* in zephyr/dts/arm/renesas/ra/ra6/ra6-cm33-common.dtsi:519 */
			clocks = < &pclkd 0x4 0x1e >;  /* in zephyr/dts/arm/renesas/ra/ra6/ra6-cm33-common.dtsi:520 */
			reg = < 0x40169100 0x100 >;    /* in zephyr/dts/arm/renesas/ra/ra6/ra6-cm33-common.dtsi:521 */
			#pwm-cells = < 0x3 >;          /* in zephyr/dts/arm/renesas/ra/ra6/ra6-cm33-common.dtsi:522 */
			pinctrl-0 = < &pwm1_default >; /* in zephyr/boards/renesas/ek_ra6e2/ek_ra6e2.dts:172 */
			pinctrl-names = "default";     /* in zephyr/boards/renesas/ek_ra6e2/ek_ra6e2.dts:173 */
			interrupts = < 0x3f 0x1 >,
			             < 0x40 0x1 >;     /* in zephyr/boards/renesas/ek_ra6e2/ek_ra6e2.dts:174 */
			interrupt-names = "gtioca",
			                  "overflow";  /* in zephyr/boards/renesas/ek_ra6e2/ek_ra6e2.dts:175 */
			divider = < 0x8 >;             /* in zephyr/boards/renesas/ek_ra6e2/ek_ra6e2.dts:176 */
			status = "okay";               /* in zephyr/boards/renesas/ek_ra6e2/ek_ra6e2.dts:177 */
		};

		/* node '/soc/pwm2@40169200' defined in zephyr/dts/arm/renesas/ra/ra6/ra6-cm33-common.dtsi:526 */
		pwm2: pwm2@40169200 {
			compatible = "renesas,ra-pwm"; /* in zephyr/dts/arm/renesas/ra/ra6/ra6-cm33-common.dtsi:527 */
			divider = < 0x0 >;             /* in zephyr/dts/arm/renesas/ra/ra6/ra6-cm33-common.dtsi:528 */
			channel = < 0x2 >;             /* in zephyr/dts/arm/renesas/ra/ra6/ra6-cm33-common.dtsi:529 */
			clocks = < &pclkd 0x4 0x1d >;  /* in zephyr/dts/arm/renesas/ra/ra6/ra6-cm33-common.dtsi:530 */
			reg = < 0x40169200 0x100 >;    /* in zephyr/dts/arm/renesas/ra/ra6/ra6-cm33-common.dtsi:531 */
			#pwm-cells = < 0x3 >;          /* in zephyr/dts/arm/renesas/ra/ra6/ra6-cm33-common.dtsi:532 */
			status = "disabled";           /* in zephyr/dts/arm/renesas/ra/ra6/ra6-cm33-common.dtsi:533 */
		};

		/* node '/soc/pwm4@40169400' defined in zephyr/dts/arm/renesas/ra/ra6/ra6-cm33-common.dtsi:536 */
		pwm4: pwm4@40169400 {
			compatible = "renesas,ra-pwm"; /* in zephyr/dts/arm/renesas/ra/ra6/ra6-cm33-common.dtsi:537 */
			divider = < 0x0 >;             /* in zephyr/dts/arm/renesas/ra/ra6/ra6-cm33-common.dtsi:538 */
			channel = < 0x4 >;             /* in zephyr/dts/arm/renesas/ra/ra6/ra6-cm33-common.dtsi:539 */
			clocks = < &pclkd 0x4 0x1b >;  /* in zephyr/dts/arm/renesas/ra/ra6/ra6-cm33-common.dtsi:540 */
			reg = < 0x40169400 0x100 >;    /* in zephyr/dts/arm/renesas/ra/ra6/ra6-cm33-common.dtsi:541 */
			#pwm-cells = < 0x3 >;          /* in zephyr/dts/arm/renesas/ra/ra6/ra6-cm33-common.dtsi:542 */
			status = "disabled";           /* in zephyr/dts/arm/renesas/ra/ra6/ra6-cm33-common.dtsi:543 */
		};

		/* node '/soc/pwm5@40169500' defined in zephyr/dts/arm/renesas/ra/ra6/ra6-cm33-common.dtsi:546 */
		pwm5: pwm5@40169500 {
			compatible = "renesas,ra-pwm"; /* in zephyr/dts/arm/renesas/ra/ra6/ra6-cm33-common.dtsi:547 */
			divider = < 0x0 >;             /* in zephyr/dts/arm/renesas/ra/ra6/ra6-cm33-common.dtsi:548 */
			channel = < 0x5 >;             /* in zephyr/dts/arm/renesas/ra/ra6/ra6-cm33-common.dtsi:549 */
			clocks = < &pclkd 0x4 0x1a >;  /* in zephyr/dts/arm/renesas/ra/ra6/ra6-cm33-common.dtsi:550 */
			reg = < 0x40169500 0x100 >;    /* in zephyr/dts/arm/renesas/ra/ra6/ra6-cm33-common.dtsi:551 */
			#pwm-cells = < 0x3 >;          /* in zephyr/dts/arm/renesas/ra/ra6/ra6-cm33-common.dtsi:552 */
			status = "disabled";           /* in zephyr/dts/arm/renesas/ra/ra6/ra6-cm33-common.dtsi:553 */
		};

		/* node '/soc/wdt@40083400' defined in zephyr/dts/arm/renesas/ra/ra6/ra6-cm33-common.dtsi:556 */
		wdt: wdt@40083400 {
			compatible = "renesas,ra-wdt"; /* in zephyr/dts/arm/renesas/ra/ra6/ra6-cm33-common.dtsi:557 */
			reg = < 0x40083400 0x200 >;    /* in zephyr/dts/arm/renesas/ra/ra6/ra6-cm33-common.dtsi:558 */
			clocks = < &pclkb 0x0 0x0 >;   /* in zephyr/dts/arm/renesas/ra/ra6/ra6-cm33-common.dtsi:559 */
			status = "okay";               /* in zephyr/boards/renesas/ek_ra6e2/ek_ra6e2.dts:198 */
		};

		/* node '/soc/ctsua@40081000' defined in zephyr/dts/arm/renesas/ra/ra6/ra6-cm33-common.dtsi:579 */
		ctsu: ctsua@40081000 {
			compatible = "renesas,ra-ctsu"; /* in zephyr/dts/arm/renesas/ra/ra6/ra6-cm33-common.dtsi:580 */
			reg = < 0x40081000 0x24 >;      /* in zephyr/dts/arm/renesas/ra/ra6/ra6-cm33-common.dtsi:581 */
			clocks = < &pclkb 0x2 0x3 >;    /* in zephyr/dts/arm/renesas/ra/ra6/ra6-cm33-common.dtsi:582 */
			variant = "ctsua";              /* in zephyr/dts/arm/renesas/ra/ra6/ra6-cm33-common.dtsi:583 */
			status = "disabled";            /* in zephyr/dts/arm/renesas/ra/ra6/ra6-cm33-common.dtsi:584 */
		};

		/* node '/soc/qspi0@64000000' defined in zephyr/dts/arm/renesas/ra/ra6/ra6-cm33-common.dtsi:587 */
		qspi0: qspi0@64000000 {
			compatible = "renesas,ra-qspi"; /* in zephyr/dts/arm/renesas/ra/ra6/ra6-cm33-common.dtsi:588 */
			#address-cells = < 0x1 >;       /* in zephyr/dts/arm/renesas/ra/ra6/ra6-cm33-common.dtsi:589 */
			#size-cells = < 0x1 >;          /* in zephyr/dts/arm/renesas/ra/ra6/ra6-cm33-common.dtsi:590 */
			reg = < 0x64000000 0x808 >;     /* in zephyr/dts/arm/renesas/ra/ra6/ra6-cm33-common.dtsi:591 */
			pinctrl-0 = < &qspi_default >;  /* in zephyr/boards/renesas/ek_ra6e2/ek_ra6e2.dts:202 */
			pinctrl-names = "default";      /* in zephyr/boards/renesas/ek_ra6e2/ek_ra6e2.dts:203 */
			status = "okay";                /* in zephyr/boards/renesas/ek_ra6e2/ek_ra6e2.dts:204 */

			/* node '/soc/qspi0@64000000/qspi-nor-flash@60000000' defined in zephyr/boards/renesas/ek_ra6e2/ek_ra6e2.dts:206 */
			at25sf128a: qspi-nor-flash@60000000 {
				compatible = "renesas,ra-qspi-nor"; /* in zephyr/boards/renesas/ek_ra6e2/ek_ra6e2.dts:207 */
				reg = < 0x60000000 0x1000000 >;     /* in zephyr/boards/renesas/ek_ra6e2/ek_ra6e2.dts:208 */
				status = "okay";                    /* in zephyr/boards/renesas/ek_ra6e2/ek_ra6e2.dts:209 */
				write-block-size = < 0x1 >;         /* in zephyr/boards/renesas/ek_ra6e2/ek_ra6e2.dts:210 */
				erase-block-size = < 0x1000 >;      /* in zephyr/boards/renesas/ek_ra6e2/ek_ra6e2.dts:211 */
			};
		};

		/* node '/soc/memory@20000000' defined in zephyr/dts/arm/renesas/ra/ra6/r7fa6e2bx.dtsi:26 */
		sram0: memory@20000000 {
			compatible = "mmio-sram";    /* in zephyr/dts/arm/renesas/ra/ra6/r7fa6e2bx.dtsi:27 */
			reg = < 0x20000000 0xa000 >; /* in zephyr/dts/arm/renesas/ra/ra6/r7fa6e2bx.dtsi:28 */
		};

		/* node '/soc/gpio@40080100' defined in zephyr/dts/arm/renesas/ra/ra6/r7fa6e2bx.dtsi:31 */
		ioport8: gpio@40080100 {
			compatible = "renesas,ra-gpio-ioport"; /* in zephyr/dts/arm/renesas/ra/ra6/r7fa6e2bx.dtsi:32 */
			reg = < 0x40080100 0x20 >;             /* in zephyr/dts/arm/renesas/ra/ra6/r7fa6e2bx.dtsi:33 */
			port = < 0x8 >;                        /* in zephyr/dts/arm/renesas/ra/ra6/r7fa6e2bx.dtsi:34 */
			gpio-controller;                       /* in zephyr/dts/arm/renesas/ra/ra6/r7fa6e2bx.dtsi:35 */
			#gpio-cells = < 0x2 >;                 /* in zephyr/dts/arm/renesas/ra/ra6/r7fa6e2bx.dtsi:36 */
			ngpios = < 0x10 >;                     /* in zephyr/dts/arm/renesas/ra/ra6/r7fa6e2bx.dtsi:37 */
			status = "disabled";                   /* in zephyr/dts/arm/renesas/ra/ra6/r7fa6e2bx.dtsi:38 */
			port-irqs = < &port_irq11 >;           /* in zephyr/dts/arm/renesas/ra/ra6/r7fa6e2bx.dtsi:369 */
			port-irq-names = "port-irq11";         /* in zephyr/dts/arm/renesas/ra/ra6/r7fa6e2bx.dtsi:370 */
			port-irq11-pins = < 0xe >;             /* in zephyr/dts/arm/renesas/ra/ra6/r7fa6e2bx.dtsi:371 */
		};

		/* node '/soc/canfd_global@400b0000' defined in zephyr/dts/arm/renesas/ra/ra6/r7fa6e2bx.dtsi:45 */
		canfd_global: canfd_global@400b0000 {
			compatible = "renesas,ra-canfd-global"; /* in zephyr/dts/arm/renesas/ra/ra6/r7fa6e2bx.dtsi:46 */
			interrupts = < 0x28 0x1 >,
			             < 0x29 0x1 >;              /* in zephyr/dts/arm/renesas/ra/ra6/r7fa6e2bx.dtsi:47 */
			interrupt-names = "rxf",
			                  "glerr";              /* in zephyr/dts/arm/renesas/ra/ra6/r7fa6e2bx.dtsi:48 */
			clocks = < &pclkb 0x0 0x0 >,
			         < &pclka 0x0 0x0 >;            /* in zephyr/dts/arm/renesas/ra/ra6/r7fa6e2bx.dtsi:49 */
			clock-names = "opclk",
			              "ramclk";                 /* in zephyr/dts/arm/renesas/ra/ra6/r7fa6e2bx.dtsi:50 */
			dll-max-freq = < 0x2625a00 >;           /* in zephyr/dts/arm/renesas/ra/ra6/r7fa6e2bx.dtsi:51 */
			reg = < 0x400b0000 0x2000 >;            /* in zephyr/dts/arm/renesas/ra/ra6/r7fa6e2bx.dtsi:52 */
			status = "okay";                        /* in zephyr/boards/renesas/ek_ra6e2/ek_ra6e2.dts:135 */

			/* node '/soc/canfd_global@400b0000/canfd0' defined in zephyr/dts/arm/renesas/ra/ra6/r7fa6e2bx.dtsi:55 */
			canfd0: canfd0 {
				compatible = "renesas,ra-canfd"; /* in zephyr/dts/arm/renesas/ra/ra6/r7fa6e2bx.dtsi:56 */
				channel = < 0x0 >;               /* in zephyr/dts/arm/renesas/ra/ra6/r7fa6e2bx.dtsi:57 */
				interrupts = < 0x2b 0xc >,
				             < 0x2c 0xc >,
				             < 0x2d 0xc >;       /* in zephyr/dts/arm/renesas/ra/ra6/r7fa6e2bx.dtsi:58 */
				interrupt-names = "err",
				                  "tx",
				                  "rx";          /* in zephyr/dts/arm/renesas/ra/ra6/r7fa6e2bx.dtsi:59 */
				clocks = < &canfdclk 0x2 0x1b >; /* in zephyr/dts/arm/renesas/ra/ra6/r7fa6e2bx.dtsi:60 */
				clock-names = "dllclk";          /* in zephyr/dts/arm/renesas/ra/ra6/r7fa6e2bx.dtsi:61 */
				pinctrl-0 = < &canfd0_default >; /* in zephyr/boards/renesas/ek_ra6e2/ek_ra6e2.dts:138 */
				pinctrl-names = "default";       /* in zephyr/boards/renesas/ek_ra6e2/ek_ra6e2.dts:139 */
				rx-max-filters = < 0x10 >;       /* in zephyr/boards/renesas/ek_ra6e2/ek_ra6e2.dts:140 */
				status = "okay";                 /* in zephyr/boards/renesas/ek_ra6e2/ek_ra6e2.dts:141 */

				/* node '/soc/canfd_global@400b0000/canfd0/can-transceiver' defined in zephyr/boards/renesas/ek_ra6e2/ek_ra6e2.dts:143 */
				can-transceiver {
					max-bitrate = < 0x4c4b40 >; /* in zephyr/boards/renesas/ek_ra6e2/ek_ra6e2.dts:144 */
				};
			};
		};

		/* node '/soc/pwm0@40169000' defined in zephyr/dts/arm/renesas/ra/ra6/r7fa6e2bx.dtsi:66 */
		pwm0: pwm0@40169000 {
			compatible = "renesas,ra-pwm"; /* in zephyr/dts/arm/renesas/ra/ra6/r7fa6e2bx.dtsi:67 */
			divider = < 0x0 >;             /* in zephyr/dts/arm/renesas/ra/ra6/r7fa6e2bx.dtsi:68 */
			channel = < 0x0 >;             /* in zephyr/dts/arm/renesas/ra/ra6/r7fa6e2bx.dtsi:69 */
			clocks = < &pclkd 0x4 0x1f >;  /* in zephyr/dts/arm/renesas/ra/ra6/r7fa6e2bx.dtsi:70 */
			reg = < 0x40169000 0x100 >;    /* in zephyr/dts/arm/renesas/ra/ra6/r7fa6e2bx.dtsi:71 */
			#pwm-cells = < 0x3 >;          /* in zephyr/dts/arm/renesas/ra/ra6/r7fa6e2bx.dtsi:72 */
			status = "disabled";           /* in zephyr/dts/arm/renesas/ra/ra6/r7fa6e2bx.dtsi:73 */
		};

		/* node '/soc/pwm3@40169300' defined in zephyr/dts/arm/renesas/ra/ra6/r7fa6e2bx.dtsi:76 */
		pwm3: pwm3@40169300 {
			compatible = "renesas,ra-pwm"; /* in zephyr/dts/arm/renesas/ra/ra6/r7fa6e2bx.dtsi:77 */
			divider = < 0x0 >;             /* in zephyr/dts/arm/renesas/ra/ra6/r7fa6e2bx.dtsi:78 */
			channel = < 0x3 >;             /* in zephyr/dts/arm/renesas/ra/ra6/r7fa6e2bx.dtsi:79 */
			clocks = < &pclkd 0x4 0x1c >;  /* in zephyr/dts/arm/renesas/ra/ra6/r7fa6e2bx.dtsi:80 */
			reg = < 0x40169300 0x100 >;    /* in zephyr/dts/arm/renesas/ra/ra6/r7fa6e2bx.dtsi:81 */
			#pwm-cells = < 0x3 >;          /* in zephyr/dts/arm/renesas/ra/ra6/r7fa6e2bx.dtsi:82 */
			status = "disabled";           /* in zephyr/dts/arm/renesas/ra/ra6/r7fa6e2bx.dtsi:83 */
		};

		/* node '/soc/trng' defined in zephyr/dts/arm/renesas/ra/ra6/r7fa6e2bx.dtsi:86 */
		trng: trng {
			compatible = "renesas,ra-trng"; /* in zephyr/dts/arm/renesas/ra/ra6/r7fa6e2bx.dtsi:87 */
			status = "okay";                /* in zephyr/boards/renesas/ek_ra6e2/ek_ra6e2.dts:181 */
		};

		/* node '/soc/agtw@400e8000' defined in zephyr/dts/arm/renesas/ra/ra6/r7fa6e2bx.dtsi:91 */
		agt0: agtw@400e8000 {
			compatible = "renesas,ra-agt";           /* in zephyr/dts/arm/renesas/ra/ra6/r7fa6e2bx.dtsi:92 */
			channel = < 0x0 >;                       /* in zephyr/dts/arm/renesas/ra/ra6/r7fa6e2bx.dtsi:93 */
			reg = < 0x400e8000 0x100 >;              /* in zephyr/dts/arm/renesas/ra/ra6/r7fa6e2bx.dtsi:94 */
			renesas,count-source = "AGT_CLOCK_LOCO"; /* in zephyr/dts/arm/renesas/ra/ra6/r7fa6e2bx.dtsi:95 */
			renesas,prescaler = < 0x0 >;             /* in zephyr/dts/arm/renesas/ra/ra6/r7fa6e2bx.dtsi:96 */
			renesas,resolution = < 0x20 >;           /* in zephyr/dts/arm/renesas/ra/ra6/r7fa6e2bx.dtsi:97 */
			status = "disabled";                     /* in zephyr/dts/arm/renesas/ra/ra6/r7fa6e2bx.dtsi:98 */

			/* node '/soc/agtw@400e8000/counter' defined in zephyr/dts/arm/renesas/ra/ra6/r7fa6e2bx.dtsi:100 */
			counter {
				compatible = "renesas,ra-agt-counter"; /* in zephyr/dts/arm/renesas/ra/ra6/r7fa6e2bx.dtsi:101 */
				status = "disabled";                   /* in zephyr/dts/arm/renesas/ra/ra6/r7fa6e2bx.dtsi:102 */
			};
		};

		/* node '/soc/agtw@400e8100' defined in zephyr/dts/arm/renesas/ra/ra6/r7fa6e2bx.dtsi:106 */
		agt1: agtw@400e8100 {
			compatible = "renesas,ra-agt";           /* in zephyr/dts/arm/renesas/ra/ra6/r7fa6e2bx.dtsi:107 */
			channel = < 0x1 >;                       /* in zephyr/dts/arm/renesas/ra/ra6/r7fa6e2bx.dtsi:108 */
			reg = < 0x400e8100 0x100 >;              /* in zephyr/dts/arm/renesas/ra/ra6/r7fa6e2bx.dtsi:109 */
			renesas,count-source = "AGT_CLOCK_LOCO"; /* in zephyr/dts/arm/renesas/ra/ra6/r7fa6e2bx.dtsi:110 */
			renesas,prescaler = < 0x0 >;             /* in zephyr/dts/arm/renesas/ra/ra6/r7fa6e2bx.dtsi:111 */
			renesas,resolution = < 0x20 >;           /* in zephyr/dts/arm/renesas/ra/ra6/r7fa6e2bx.dtsi:112 */
			status = "disabled";                     /* in zephyr/dts/arm/renesas/ra/ra6/r7fa6e2bx.dtsi:113 */

			/* node '/soc/agtw@400e8100/counter' defined in zephyr/dts/arm/renesas/ra/ra6/r7fa6e2bx.dtsi:115 */
			counter {
				compatible = "renesas,ra-agt-counter"; /* in zephyr/dts/arm/renesas/ra/ra6/r7fa6e2bx.dtsi:116 */
				status = "disabled";                   /* in zephyr/dts/arm/renesas/ra/ra6/r7fa6e2bx.dtsi:117 */
			};
		};

		/* node '/soc/option-setting-ofs0@100a100' defined in zephyr/dts/arm/renesas/ra/ra6/r7fa6e2bx.dtsi:121 */
		option_setting_ofs0: option-setting-ofs0@100a100 {
			compatible = "zephyr,memory-region";      /* in zephyr/dts/arm/renesas/ra/ra6/r7fa6e2bx.dtsi:122 */
			zephyr,memory-region = "OFS_OFS0_MEMORY"; /* in zephyr/dts/arm/renesas/ra/ra6/r7fa6e2bx.dtsi:123 */
			reg = < 0x100a100 0x4 >;                  /* in zephyr/dts/arm/renesas/ra/ra6/r7fa6e2bx.dtsi:124 */
			status = "okay";                          /* in zephyr/dts/arm/renesas/ra/ra6/r7fa6e2bx.dtsi:125 */
		};

		/* node '/soc/option-setting-osis@100a120' defined in zephyr/dts/arm/renesas/ra/ra6/r7fa6e2bx.dtsi:128 */
		option_setting_osis: option-setting-osis@100a120 {
			compatible = "zephyr,memory-region";      /* in zephyr/dts/arm/renesas/ra/ra6/r7fa6e2bx.dtsi:129 */
			zephyr,memory-region = "OFS_OSIS_MEMORY"; /* in zephyr/dts/arm/renesas/ra/ra6/r7fa6e2bx.dtsi:130 */
			reg = < 0x100a120 0x10 >;                 /* in zephyr/dts/arm/renesas/ra/ra6/r7fa6e2bx.dtsi:131 */
			status = "okay";                          /* in zephyr/dts/arm/renesas/ra/ra6/r7fa6e2bx.dtsi:132 */
		};

		/* node '/soc/option-setting-ofs1-sec@100a200' defined in zephyr/dts/arm/renesas/ra/ra6/r7fa6e2bx.dtsi:135 */
		option_setting_ofs1_sec: option-setting-ofs1-sec@100a200 {
			compatible = "zephyr,memory-region";          /* in zephyr/dts/arm/renesas/ra/ra6/r7fa6e2bx.dtsi:136 */
			zephyr,memory-region = "OFS_OFS1_SEC_MEMORY"; /* in zephyr/dts/arm/renesas/ra/ra6/r7fa6e2bx.dtsi:137 */
			reg = < 0x100a200 0x4 >;                      /* in zephyr/dts/arm/renesas/ra/ra6/r7fa6e2bx.dtsi:138 */
			status = "okay";                              /* in zephyr/dts/arm/renesas/ra/ra6/r7fa6e2bx.dtsi:139 */
		};

		/* node '/soc/option-setting-bps-sec@100a240' defined in zephyr/dts/arm/renesas/ra/ra6/r7fa6e2bx.dtsi:142 */
		option_setting_bps_sec: option-setting-bps-sec@100a240 {
			compatible = "zephyr,memory-region";         /* in zephyr/dts/arm/renesas/ra/ra6/r7fa6e2bx.dtsi:143 */
			zephyr,memory-region = "OFS_BPS_SEC_MEMORY"; /* in zephyr/dts/arm/renesas/ra/ra6/r7fa6e2bx.dtsi:144 */
			reg = < 0x100a240 0x4 >;                     /* in zephyr/dts/arm/renesas/ra/ra6/r7fa6e2bx.dtsi:145 */
			status = "okay";                             /* in zephyr/dts/arm/renesas/ra/ra6/r7fa6e2bx.dtsi:146 */
		};

		/* node '/soc/option-setting-pbps-sec@100a260' defined in zephyr/dts/arm/renesas/ra/ra6/r7fa6e2bx.dtsi:149 */
		option_setting_pbps_sec: option-setting-pbps-sec@100a260 {
			compatible = "zephyr,memory-region";          /* in zephyr/dts/arm/renesas/ra/ra6/r7fa6e2bx.dtsi:150 */
			zephyr,memory-region = "OFS_PBPS_SEC_MEMORY"; /* in zephyr/dts/arm/renesas/ra/ra6/r7fa6e2bx.dtsi:151 */
			reg = < 0x100a260 0x4 >;                      /* in zephyr/dts/arm/renesas/ra/ra6/r7fa6e2bx.dtsi:152 */
			status = "okay";                              /* in zephyr/dts/arm/renesas/ra/ra6/r7fa6e2bx.dtsi:153 */
		};
	};

	/* node '/cpus' defined in zephyr/dts/arm/renesas/ra/ra6/ra6-cm33-common.dtsi:15 */
	cpus {
		#address-cells = < 0x1 >; /* in zephyr/dts/arm/renesas/ra/ra6/ra6-cm33-common.dtsi:16 */
		#size-cells = < 0x0 >;    /* in zephyr/dts/arm/renesas/ra/ra6/ra6-cm33-common.dtsi:17 */

		/* node '/cpus/cpu@0' defined in zephyr/dts/arm/renesas/ra/ra6/ra6-cm33-common.dtsi:19 */
		cpu@0 {
			device_type = "cpu";           /* in zephyr/dts/arm/renesas/ra/ra6/ra6-cm33-common.dtsi:20 */
			compatible = "arm,cortex-m33"; /* in zephyr/dts/arm/renesas/ra/ra6/ra6-cm33-common.dtsi:21 */
			reg = < 0x0 >;                 /* in zephyr/dts/arm/renesas/ra/ra6/ra6-cm33-common.dtsi:22 */
			#address-cells = < 0x1 >;      /* in zephyr/dts/arm/renesas/ra/ra6/ra6-cm33-common.dtsi:23 */
			#size-cells = < 0x1 >;         /* in zephyr/dts/arm/renesas/ra/ra6/ra6-cm33-common.dtsi:24 */

			/* node '/cpus/cpu@0/mpu@e000ed90' defined in zephyr/dts/arm/renesas/ra/ra6/ra6-cm33-common.dtsi:26 */
			mpu: mpu@e000ed90 {
				compatible = "arm,armv8m-mpu"; /* in zephyr/dts/arm/renesas/ra/ra6/ra6-cm33-common.dtsi:27 */
				reg = < 0xe000ed90 0x40 >;     /* in zephyr/dts/arm/renesas/ra/ra6/ra6-cm33-common.dtsi:28 */
			};
		};
	};

	/* node '/clocks' defined in zephyr/dts/arm/renesas/ra/ra6/r7fa6e2bx.dtsi:157 */
	clocks: clocks {
		#address-cells = < 0x1 >; /* in zephyr/dts/arm/renesas/ra/ra6/r7fa6e2bx.dtsi:158 */
		#size-cells = < 0x1 >;    /* in zephyr/dts/arm/renesas/ra/ra6/r7fa6e2bx.dtsi:159 */

		/* node '/clocks/clock-main-osc' defined in zephyr/dts/arm/renesas/ra/ra6/r7fa6e2bx.dtsi:161 */
		xtal: clock-main-osc {
			compatible = "renesas,ra-cgc-external-clock"; /* in zephyr/dts/arm/renesas/ra/ra6/r7fa6e2bx.dtsi:162 */
			clock-frequency = < 0x1312d00 >;              /* in zephyr/boards/renesas/ek_ra6e2/ek_ra6e2.dts:111 */
			mosel = < 0x0 >;                              /* in zephyr/boards/renesas/ek_ra6e2/ek_ra6e2.dts:112 */
			#clock-cells = < 0x0 >;                       /* in zephyr/boards/renesas/ek_ra6e2/ek_ra6e2.dts:113 */
			status = "okay";                              /* in zephyr/boards/renesas/ek_ra6e2/ek_ra6e2.dts:114 */
			phandle = < 0x1e >;                           /* in zephyr/boards/renesas/ek_ra6e2/ek_ra6e2.dts:122 */
		};

		/* node '/clocks/clock-hoco' defined in zephyr/dts/arm/renesas/ra/ra6/r7fa6e2bx.dtsi:168 */
		hoco: clock-hoco {
			compatible = "fixed-clock";      /* in zephyr/dts/arm/renesas/ra/ra6/r7fa6e2bx.dtsi:169 */
			clock-frequency = < 0x1312d00 >; /* in zephyr/dts/arm/renesas/ra/ra6/r7fa6e2bx.dtsi:170 */
			#clock-cells = < 0x0 >;          /* in zephyr/dts/arm/renesas/ra/ra6/r7fa6e2bx.dtsi:171 */
		};

		/* node '/clocks/clock-moco' defined in zephyr/dts/arm/renesas/ra/ra6/r7fa6e2bx.dtsi:174 */
		moco: clock-moco {
			compatible = "fixed-clock";     /* in zephyr/dts/arm/renesas/ra/ra6/r7fa6e2bx.dtsi:175 */
			clock-frequency = < 0x7a1200 >; /* in zephyr/dts/arm/renesas/ra/ra6/r7fa6e2bx.dtsi:176 */
			#clock-cells = < 0x0 >;         /* in zephyr/dts/arm/renesas/ra/ra6/r7fa6e2bx.dtsi:177 */
		};

		/* node '/clocks/clock-loco' defined in zephyr/dts/arm/renesas/ra/ra6/r7fa6e2bx.dtsi:180 */
		loco: clock-loco {
			compatible = "fixed-clock";   /* in zephyr/dts/arm/renesas/ra/ra6/r7fa6e2bx.dtsi:181 */
			clock-frequency = < 0x8000 >; /* in zephyr/dts/arm/renesas/ra/ra6/r7fa6e2bx.dtsi:182 */
			#clock-cells = < 0x0 >;       /* in zephyr/dts/arm/renesas/ra/ra6/r7fa6e2bx.dtsi:183 */
		};

		/* node '/clocks/clock-subclk' defined in zephyr/dts/arm/renesas/ra/ra6/r7fa6e2bx.dtsi:186 */
		subclk: clock-subclk {
			compatible = "renesas,ra-cgc-subclk"; /* in zephyr/dts/arm/renesas/ra/ra6/r7fa6e2bx.dtsi:187 */
			clock-frequency = < 0x8000 >;         /* in zephyr/dts/arm/renesas/ra/ra6/r7fa6e2bx.dtsi:188 */
			#clock-cells = < 0x0 >;               /* in zephyr/dts/arm/renesas/ra/ra6/r7fa6e2bx.dtsi:189 */
			status = "okay";                      /* in zephyr/boards/renesas/ek_ra6e2/ek_ra6e2.dts:118 */
		};

		/* node '/clocks/pll' defined in zephyr/dts/arm/renesas/ra/ra6/r7fa6e2bx.dtsi:193 */
		pll: pll {
			compatible = "renesas,ra-cgc-pll"; /* in zephyr/dts/arm/renesas/ra/ra6/r7fa6e2bx.dtsi:194 */
			#clock-cells = < 0x0 >;            /* in zephyr/dts/arm/renesas/ra/ra6/r7fa6e2bx.dtsi:195 */
			clocks = < &xtal >;                /* in zephyr/boards/renesas/ek_ra6e2/ek_ra6e2.dts:122 */
			div = < 0x1 >;                     /* in zephyr/boards/renesas/ek_ra6e2/ek_ra6e2.dts:123 */
			mul = < 0xa 0x0 >;                 /* in zephyr/boards/renesas/ek_ra6e2/ek_ra6e2.dts:124 */
			status = "okay";                   /* in zephyr/boards/renesas/ek_ra6e2/ek_ra6e2.dts:125 */
			phandle = < 0x1f >;                /* in zephyr/dts/arm/renesas/ra/ra6/r7fa6e2bx.dtsi:211 */
		};

		/* node '/clocks/pclkblock@40084000' defined in zephyr/dts/arm/renesas/ra/ra6/r7fa6e2bx.dtsi:204 */
		pclkblock: pclkblock@40084000 {
			compatible = "renesas,ra-cgc-pclk-block"; /* in zephyr/dts/arm/renesas/ra/ra6/r7fa6e2bx.dtsi:205 */
			reg = < 0x40084000 0x4 >,
			      < 0x40084004 0x4 >,
			      < 0x40084008 0x4 >,
			      < 0x4008400c 0x4 >,
			      < 0x40084010 0x4 >;                 /* in zephyr/dts/arm/renesas/ra/ra6/r7fa6e2bx.dtsi:206 */
			reg-names = "MSTPA",
			            "MSTPB",
			            "MSTPC",
			            "MSTPD",
			            "MSTPE";                      /* in zephyr/dts/arm/renesas/ra/ra6/r7fa6e2bx.dtsi:208 */
			#clock-cells = < 0x0 >;                   /* in zephyr/dts/arm/renesas/ra/ra6/r7fa6e2bx.dtsi:210 */
			clocks = < &pll >;                        /* in zephyr/dts/arm/renesas/ra/ra6/r7fa6e2bx.dtsi:211 */
			status = "okay";                          /* in zephyr/dts/arm/renesas/ra/ra6/r7fa6e2bx.dtsi:212 */

			/* node '/clocks/pclkblock@40084000/iclk' defined in zephyr/dts/arm/renesas/ra/ra6/r7fa6e2bx.dtsi:214 */
			iclk: iclk {
				compatible = "renesas,ra-cgc-pclk"; /* in zephyr/dts/arm/renesas/ra/ra6/r7fa6e2bx.dtsi:215 */
				clock-frequency = < 0xbebc200 >;    /* in zephyr/dts/arm/renesas/ra/ra6/r7fa6e2bx.dtsi:216 */
				div = < 0x1 >;                      /* in zephyr/dts/arm/renesas/ra/ra6/r7fa6e2bx.dtsi:217 */
				#clock-cells = < 0x2 >;             /* in zephyr/dts/arm/renesas/ra/ra6/r7fa6e2bx.dtsi:218 */
				status = "okay";                    /* in zephyr/dts/arm/renesas/ra/ra6/r7fa6e2bx.dtsi:219 */
				phandle = < 0x12 >;                 /* in zephyr/dts/arm/renesas/ra/ra6/ra6-cm33-common.dtsi:115 */
			};

			/* node '/clocks/pclkblock@40084000/pclka' defined in zephyr/dts/arm/renesas/ra/ra6/r7fa6e2bx.dtsi:222 */
			pclka: pclka {
				compatible = "renesas,ra-cgc-pclk"; /* in zephyr/dts/arm/renesas/ra/ra6/r7fa6e2bx.dtsi:223 */
				div = < 0x2 >;                      /* in zephyr/dts/arm/renesas/ra/ra6/r7fa6e2bx.dtsi:224 */
				#clock-cells = < 0x2 >;             /* in zephyr/dts/arm/renesas/ra/ra6/r7fa6e2bx.dtsi:225 */
				status = "okay";                    /* in zephyr/dts/arm/renesas/ra/ra6/r7fa6e2bx.dtsi:226 */
				phandle = < 0x13 >;                 /* in zephyr/dts/arm/renesas/ra/ra6/ra6-cm33-common.dtsi:132 */
			};

			/* node '/clocks/pclkblock@40084000/pclkb' defined in zephyr/dts/arm/renesas/ra/ra6/r7fa6e2bx.dtsi:229 */
			pclkb: pclkb {
				compatible = "renesas,ra-cgc-pclk"; /* in zephyr/dts/arm/renesas/ra/ra6/r7fa6e2bx.dtsi:230 */
				div = < 0x4 >;                      /* in zephyr/dts/arm/renesas/ra/ra6/r7fa6e2bx.dtsi:231 */
				#clock-cells = < 0x2 >;             /* in zephyr/dts/arm/renesas/ra/ra6/r7fa6e2bx.dtsi:232 */
				status = "okay";                    /* in zephyr/dts/arm/renesas/ra/ra6/r7fa6e2bx.dtsi:233 */
				phandle = < 0x2 >;                  /* in zephyr/dts/arm/renesas/ra/ra6/ra6-cm33-common.dtsi:46 */
			};

			/* node '/clocks/pclkblock@40084000/pclkc' defined in zephyr/dts/arm/renesas/ra/ra6/r7fa6e2bx.dtsi:236 */
			pclkc: pclkc {
				compatible = "renesas,ra-cgc-pclk"; /* in zephyr/dts/arm/renesas/ra/ra6/r7fa6e2bx.dtsi:237 */
				div = < 0x4 >;                      /* in zephyr/dts/arm/renesas/ra/ra6/r7fa6e2bx.dtsi:238 */
				#clock-cells = < 0x2 >;             /* in zephyr/dts/arm/renesas/ra/ra6/r7fa6e2bx.dtsi:239 */
				status = "okay";                    /* in zephyr/dts/arm/renesas/ra/ra6/r7fa6e2bx.dtsi:240 */
			};

			/* node '/clocks/pclkblock@40084000/pclkd' defined in zephyr/dts/arm/renesas/ra/ra6/r7fa6e2bx.dtsi:243 */
			pclkd: pclkd {
				compatible = "renesas,ra-cgc-pclk"; /* in zephyr/dts/arm/renesas/ra/ra6/r7fa6e2bx.dtsi:244 */
				div = < 0x2 >;                      /* in zephyr/dts/arm/renesas/ra/ra6/r7fa6e2bx.dtsi:245 */
				#clock-cells = < 0x2 >;             /* in zephyr/dts/arm/renesas/ra/ra6/r7fa6e2bx.dtsi:246 */
				status = "okay";                    /* in zephyr/dts/arm/renesas/ra/ra6/r7fa6e2bx.dtsi:247 */
				phandle = < 0x19 >;                 /* in zephyr/dts/arm/renesas/ra/ra6/ra6-cm33-common.dtsi:520 */
			};

			/* node '/clocks/pclkblock@40084000/fclk' defined in zephyr/dts/arm/renesas/ra/ra6/r7fa6e2bx.dtsi:250 */
			fclk: fclk {
				compatible = "renesas,ra-cgc-pclk"; /* in zephyr/dts/arm/renesas/ra/ra6/r7fa6e2bx.dtsi:251 */
				div = < 0x4 >;                      /* in zephyr/dts/arm/renesas/ra/ra6/r7fa6e2bx.dtsi:252 */
				#clock-cells = < 0x2 >;             /* in zephyr/dts/arm/renesas/ra/ra6/r7fa6e2bx.dtsi:253 */
				status = "okay";                    /* in zephyr/dts/arm/renesas/ra/ra6/r7fa6e2bx.dtsi:254 */
			};

			/* node '/clocks/pclkblock@40084000/clkout' defined in zephyr/dts/arm/renesas/ra/ra6/r7fa6e2bx.dtsi:257 */
			clkout: clkout {
				compatible = "renesas,ra-cgc-pclk"; /* in zephyr/dts/arm/renesas/ra/ra6/r7fa6e2bx.dtsi:258 */
				#clock-cells = < 0x2 >;             /* in zephyr/dts/arm/renesas/ra/ra6/r7fa6e2bx.dtsi:259 */
				status = "disabled";                /* in zephyr/dts/arm/renesas/ra/ra6/r7fa6e2bx.dtsi:260 */
			};

			/* node '/clocks/pclkblock@40084000/uclk' defined in zephyr/dts/arm/renesas/ra/ra6/r7fa6e2bx.dtsi:263 */
			uclk: uclk {
				compatible = "renesas,ra-cgc-pclk"; /* in zephyr/dts/arm/renesas/ra/ra6/r7fa6e2bx.dtsi:264 */
				#clock-cells = < 0x2 >;             /* in zephyr/dts/arm/renesas/ra/ra6/r7fa6e2bx.dtsi:265 */
				status = "disabled";                /* in zephyr/dts/arm/renesas/ra/ra6/r7fa6e2bx.dtsi:266 */
			};

			/* node '/clocks/pclkblock@40084000/canfdclk' defined in zephyr/dts/arm/renesas/ra/ra6/r7fa6e2bx.dtsi:269 */
			canfdclk: canfdclk {
				compatible = "renesas,ra-cgc-pclk"; /* in zephyr/dts/arm/renesas/ra/ra6/r7fa6e2bx.dtsi:270 */
				#clock-cells = < 0x2 >;             /* in zephyr/dts/arm/renesas/ra/ra6/r7fa6e2bx.dtsi:271 */
				clocks = < &pll >;                  /* in zephyr/boards/renesas/ek_ra6e2/ek_ra6e2.dts:129 */
				div = < 0x8 >;                      /* in zephyr/boards/renesas/ek_ra6e2/ek_ra6e2.dts:130 */
				status = "okay";                    /* in zephyr/boards/renesas/ek_ra6e2/ek_ra6e2.dts:131 */
				phandle = < 0x1c >;                 /* in zephyr/dts/arm/renesas/ra/ra6/r7fa6e2bx.dtsi:60 */
			};

			/* node '/clocks/pclkblock@40084000/cecclk' defined in zephyr/dts/arm/renesas/ra/ra6/r7fa6e2bx.dtsi:275 */
			cecclk: cecclk {
				compatible = "renesas,ra-cgc-pclk"; /* in zephyr/dts/arm/renesas/ra/ra6/r7fa6e2bx.dtsi:276 */
				#clock-cells = < 0x2 >;             /* in zephyr/dts/arm/renesas/ra/ra6/r7fa6e2bx.dtsi:277 */
				status = "disabled";                /* in zephyr/dts/arm/renesas/ra/ra6/r7fa6e2bx.dtsi:278 */
			};

			/* node '/clocks/pclkblock@40084000/i3cclk' defined in zephyr/dts/arm/renesas/ra/ra6/r7fa6e2bx.dtsi:281 */
			i3cclk: i3cclk {
				compatible = "renesas,ra-cgc-pclk"; /* in zephyr/dts/arm/renesas/ra/ra6/r7fa6e2bx.dtsi:282 */
				#clock-cells = < 0x2 >;             /* in zephyr/dts/arm/renesas/ra/ra6/r7fa6e2bx.dtsi:283 */
				status = "disabled";                /* in zephyr/dts/arm/renesas/ra/ra6/r7fa6e2bx.dtsi:284 */
			};
		};
	};

	/* node '/leds' defined in zephyr/boards/renesas/ek_ra6e2/ek_ra6e2.dts:30 */
	leds {
		compatible = "gpio-leds"; /* in zephyr/boards/renesas/ek_ra6e2/ek_ra6e2.dts:31 */

		/* node '/leds/led1' defined in zephyr/boards/renesas/ek_ra6e2/ek_ra6e2.dts:33 */
		led1: led1 {
			gpios = < &ioport2 0x7 0x0 >; /* in zephyr/boards/renesas/ek_ra6e2/ek_ra6e2.dts:34 */
			label = "LED1";               /* in zephyr/boards/renesas/ek_ra6e2/ek_ra6e2.dts:35 */
		};

		/* node '/leds/led2' defined in zephyr/boards/renesas/ek_ra6e2/ek_ra6e2.dts:38 */
		led2: led2 {
			gpios = < &ioport4 0x0 0x0 >; /* in zephyr/boards/renesas/ek_ra6e2/ek_ra6e2.dts:39 */
			label = "LED2";               /* in zephyr/boards/renesas/ek_ra6e2/ek_ra6e2.dts:40 */
		};

		/* node '/leds/led3' defined in zephyr/boards/renesas/ek_ra6e2/ek_ra6e2.dts:43 */
		led3: led3 {
			gpios = < &ioport1 0xd 0x0 >; /* in zephyr/boards/renesas/ek_ra6e2/ek_ra6e2.dts:44 */
			label = "LED3";               /* in zephyr/boards/renesas/ek_ra6e2/ek_ra6e2.dts:45 */
		};
	};

	/* node '/buttons' defined in zephyr/boards/renesas/ek_ra6e2/ek_ra6e2.dts:49 */
	buttons {
		compatible = "gpio-keys"; /* in zephyr/boards/renesas/ek_ra6e2/ek_ra6e2.dts:50 */

		/* node '/buttons/s1' defined in zephyr/boards/renesas/ek_ra6e2/ek_ra6e2.dts:52 */
		button0: s1 {
			gpios = < &ioport0 0x5 0x11 >;  /* in zephyr/boards/renesas/ek_ra6e2/ek_ra6e2.dts:53 */
			label = "Push button switch 1"; /* in zephyr/boards/renesas/ek_ra6e2/ek_ra6e2.dts:54 */
			zephyr,code = < 0xb >;          /* in zephyr/boards/renesas/ek_ra6e2/ek_ra6e2.dts:55 */
		};

		/* node '/buttons/s2' defined in zephyr/boards/renesas/ek_ra6e2/ek_ra6e2.dts:58 */
		button1: s2 {
			gpios = < &ioport3 0x4 0x11 >;  /* in zephyr/boards/renesas/ek_ra6e2/ek_ra6e2.dts:59 */
			label = "Push button switch 2"; /* in zephyr/boards/renesas/ek_ra6e2/ek_ra6e2.dts:60 */
			zephyr,code = < 0x2 >;          /* in zephyr/boards/renesas/ek_ra6e2/ek_ra6e2.dts:61 */
		};
	};
};
